VERSION "DNNBNNNYNYNNNNNNNNNNNNNNNNNNNNNNNNNNNNNNNN/4/%%%/4/'%**4NNN///"

NS_ :

BS_:

BU_: ADAS SENP ECU2 ECU3 ECU4 ECU5 ECU6 ECU7 ECU8 ECU9 ECU10 ECU11 ECU12 ECU13 ECU14 ECU15 ECU16 Tester Default_Receiver Handler

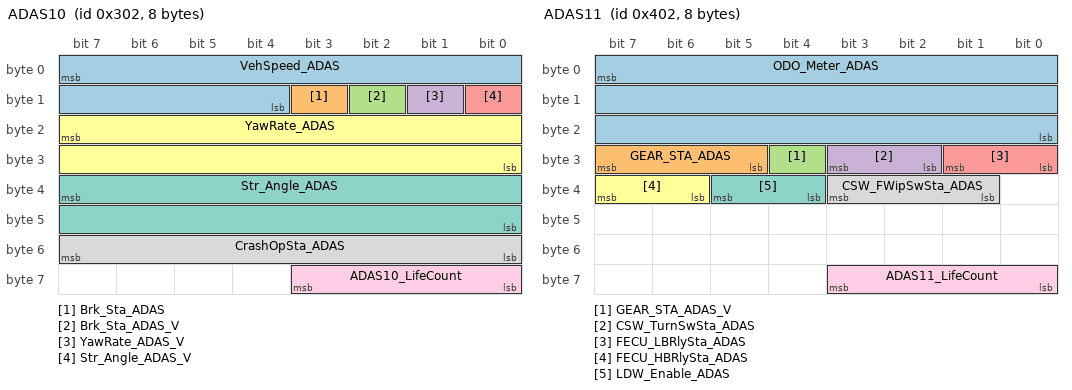
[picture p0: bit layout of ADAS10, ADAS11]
BO_ 770 ADAS10: 8 ADAS
 SG_ VehSpeed_ADAS : 7|12@0+ (0.125,0) [0|0] "km/h"  SENP
 SG_ Brk_Sta_ADAS : 11|1@0+ (1,0) [0|0] ""  SENP
 SG_ Brk_Sta_ADAS_V : 10|1@0+ (1,0) [0|0] ""  SENP
 SG_ YawRate_ADAS_V : 9|1@0+ (1,0) [0|0] ""  SENP
 SG_ Str_Angle_ADAS_V : 8|1@0+ (1,0) [0|0] ""  SENP
 SG_ YawRate_ADAS : 23|16@0+ (0.1,-100) [0|0] "deg/s"  SENP
 SG_ Str_Angle_ADAS : 39|16@0+ (0.1,-900) [0|0] "deg"  SENP
 SG_ CrashOpSta_ADAS : 55|8@0+ (1,0) [0|0] ""  SENP
 SG_ ADAS10_LifeCount : 59|4@0+ (1,0) [0|0] ""  SENP

BO_ 1026 ADAS11: 8 ADAS
 SG_ ODO_Meter_ADAS : 7|24@0+ (1,0) [0|0] "km"  SENP
 SG_ GEAR_STA_ADAS : 31|3@0+ (1,0) [0|0] ""  SENP
 SG_ GEAR_STA_ADAS_V : 28|1@0+ (1,0) [0|0] ""  SENP
 SG_ CSW_TurnSwSta_ADAS : 27|2@0+ (1,0) [0|0] ""  SENP
 SG_ FECU_LBRlySta_ADAS : 25|2@0+ (1,0) [0|0] ""  SENP
 SG_ FECU_HBRlySta_ADAS : 39|2@0+ (1,0) [0|0] ""  SENP
 SG_ LDW_Enable_ADAS : 37|2@0+ (1,0) [0|0] ""  SENP
 SG_ CSW_FWipSwSta_ADAS : 35|3@0+ (1,0) [0|0] ""  SENP
 SG_ ADAS11_LifeCount : 59|4@0+ (1,0) [0|0] ""  SENP

BO_ 1537 CaliCmd1: 8 ADAS
 SG_ EyeQ3_Aim_Request : 7|8@0+ (1,0) [0|0] ""  SENP

BO_ 1808 NMmADAS: 8 ADAS
 SG_ NM_ADAS_Zero_Byte : 7|8@0+ (1,0) [0|0] ""  Default_Receiver
 SG_ NM_ADAS_D_ES : 15|2@0+ (1,0) [0|0] ""  Default_Receiver
 SG_ NM_ADAS_AR : 10|1@0+ (1,0) [0|0] ""  SENP,ECU2,ECU3,ECU4,ECU5,ECU6,ECU7,ECU8,ECU9,ECU10,ECU11,ECU12,ECU13,ECU14,ECU15,ECU16,Tester
 SG_ NM_ADAS_SC : 9|2@0+ (1,0) [0|0] ""  SENP,ECU2,ECU3,ECU4,ECU5,ECU6,ECU7,ECU8,ECU9,ECU10,ECU11,ECU12,ECU13,ECU14,ECU15,ECU16,Tester
 SG_ NM_ADAS_AC : 23|16@0+ (1,0) [0|0] ""  Default_Receiver

BO_ 1919 DiagPhysReqToSENP: 8 ADAS
 SG_ DiagPhysReqToSENP : 7|64@0+ (1,0) [0|0] ""  SENP

BO_ 2000 DiagFuncReqFT: 8 ADAS
 SG_ DiagFuncReq : 7|64@0+ (1,0) [0|0] ""  SENP,ECU11,Default_Receiver

BO_ 784 SENP1: 8 SENP
 SG_ ME_AEB_StAFCW : 7|16@0+ (1,0) [0|0] ""  ADAS
 SG_ ME_AEB_StBFCV : 23|16@0+ (1,0) [0|0] ""  ADAS
 SG_ ME_Warning_P_Ver : 39|8@0+ (1,0) [0|0] "counter"  ADAS
 SG_ ME_AEB_MgCnt : 47|2@0+ (1,0) [0|0] ""  ADAS
 SG_ ME_AEB_Mg_V : 45|1@0+ (1,0) [0|0] ""  ADAS

BO_ 785 SENP2: 8 SENP
 SG_ ME_PEDS_L1FCW : 7|16@0+ (1,0) [0|0] ""  ADAS
 SG_ ME_PEDS_L2Prfill : 23|16@0+ (1,0) [0|0] ""  ADAS
 SG_ ME_PEDS_L3Brking : 39|16@0+ (1,0) [0|0] ""  ADAS
 SG_ ME_PEDS_MgCnt : 55|2@0+ (1,0) [0|0] ""  ADAS
 SG_ ME_PEDS_Mg_V : 53|1@0+ (1,0) [0|0] ""  ADAS

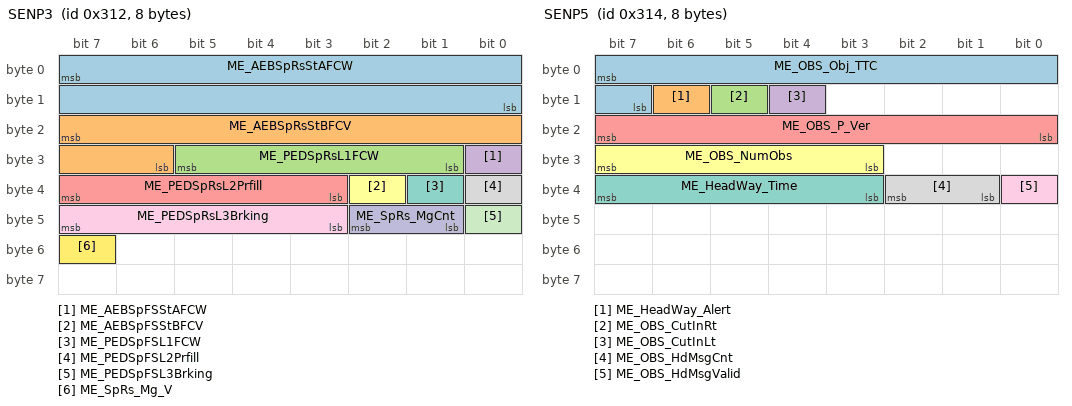
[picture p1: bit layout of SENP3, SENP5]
BO_ 786 SENP3: 8 SENP
 SG_ ME_AEBSpRsStAFCW : 7|16@0+ (1,0) [0|0] ""  ADAS
 SG_ ME_AEBSpRsStBFCV : 23|10@0+ (1,0) [0|0] ""  ADAS
 SG_ ME_PEDSpRsL1FCW : 29|5@0+ (1,0) [0|0] ""  ADAS
 SG_ ME_AEBSpFSStAFCW : 24|1@0+ (1,0) [0|0] ""  ADAS
 SG_ ME_PEDSpRsL2Prfill : 39|5@0+ (1,0) [0|0] ""  ADAS
 SG_ ME_AEBSpFSStBFCV : 34|1@0+ (1,0) [0|0] ""  ADAS
 SG_ ME_PEDSpFSL1FCW : 33|1@0+ (1,0) [0|0] ""  ADAS
 SG_ ME_PEDSpFSL2Prfill : 32|1@0+ (1,0) [0|0] ""  ADAS
 SG_ ME_PEDSpRsL3Brking : 47|5@0+ (1,0) [0|0] ""  ADAS
 SG_ ME_SpRs_MgCnt : 42|2@0+ (1,0) [0|0] ""  ADAS
 SG_ ME_PEDSpFSL3Brking : 40|1@0+ (1,0) [0|0] ""  ADAS
 SG_ ME_SpRs_Mg_V : 55|1@0+ (1,0) [0|0] ""  ADAS

BO_ 787 SENP4: 8 SENP
 SG_ ME_FS_P_Ver : 7|8@0+ (1,0) [0|0] "counter"  ADAS
 SG_ ME_FS_Info_MgCnt : 15|2@0+ (1,0) [0|0] ""  ADAS
 SG_ ME_FS_LowSun : 13|2@0+ (1,0) [0|0] ""  ADAS
 SG_ ME_FS_BlurImage : 11|2@0+ (1,0) [0|0] ""  ADAS
 SG_ ME_FS_FullBlock : 9|2@0+ (1,0) [0|0] ""  ADAS
 SG_ ME_FS_PatialBlock : 23|2@0+ (1,0) [0|0] ""  ADAS
 SG_ ME_FS_Splash : 21|2@0+ (1,0) [0|0] ""  ADAS
 SG_ ME_FS_SmearSpot : 19|2@0+ (1,0) [0|0] ""  ADAS
 SG_ ME_FS_SunRay : 17|2@0+ (1,0) [0|0] ""  ADAS
 SG_ ME_FS_SelfGlare : 31|2@0+ (1,0) [0|0] ""  ADAS
 SG_ ME_FS_FrozenWsd : 29|2@0+ (1,0) [0|0] ""  ADAS
 SG_ ME_Maintenance : 27|1@0+ (1,0) [0|0] ""  ADAS
 SG_ ME_Failsafe : 26|1@0+ (1,0) [0|0] ""  ADAS
 SG_ ME_FS_outOfFocus : 25|1@0+ (1,0) [0|0] ""  ADAS
 SG_ ME_FS_OOCY : 24|1@0+ (1,0) [0|0] ""  ADAS
 SG_ ME_FS_OOCH : 39|1@0+ (1,0) [0|0] ""  ADAS
 SG_ ME_FS_TSR_OOCY : 38|1@0+ (1,0) [0|0] ""  ADAS
 SG_ ME_FS_TSR_OOCP : 37|1@0+ (1,0) [0|0] ""  ADAS
 SG_ ME_FS_Info_Mg_V : 36|1@0+ (1,0) [0|0] ""  ADAS

BO_ 788 SENP5: 8 SENP
 SG_ ME_OBS_Obj_TTC : 7|9@0+ (0.01,0) [0|0] "sec"  ADAS
 SG_ ME_HeadWay_Alert : 14|1@0+ (1,0) [0|0] ""  ADAS
 SG_ ME_OBS_CutInRt : 13|1@0+ (1,0) [0|0] ""  ADAS
 SG_ ME_OBS_CutInLt : 12|1@0+ (1,0) [0|0] ""  ADAS
 SG_ ME_OBS_P_Ver : 23|8@0+ (1,0) [0|0] "counter"  ADAS
 SG_ ME_OBS_NumObs : 31|5@0+ (1,0) [0|0] "counter"  ADAS
 SG_ ME_HeadWay_Time : 39|5@0+ (0.1,0) [0|0] "counter"  ADAS
 SG_ ME_OBS_HdMsgCnt : 34|2@0+ (1,0) [0|0] ""  ADAS
 SG_ ME_OBS_HdMsgValid : 32|1@0+ (1,0) [0|0] ""  ADAS

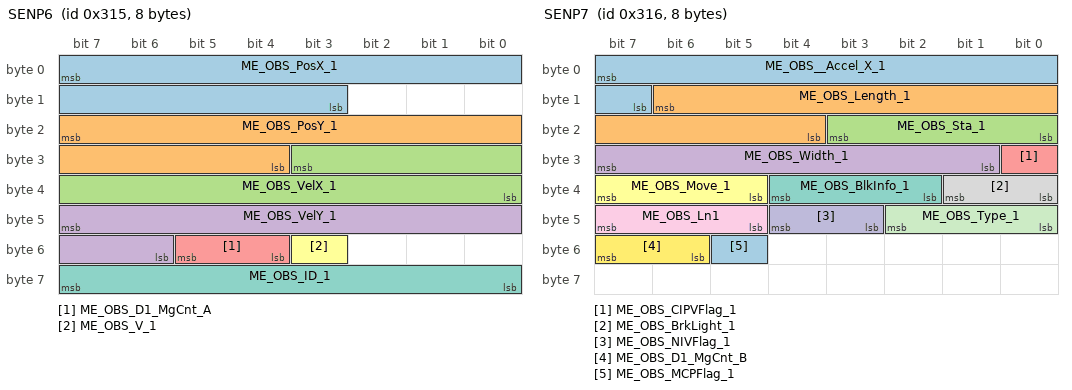
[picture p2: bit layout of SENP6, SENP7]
BO_ 789 SENP6: 8 SENP
 SG_ ME_OBS_PosX_1 : 7|13@0+ (0.05,0) [0|0] "counter"  ADAS
 SG_ ME_OBS_PosY_1 : 23|12@0+ (0.05,-102.4) [0|0] "m"  ADAS
 SG_ ME_OBS_VelX_1 : 27|12@0+ (0.05,-100) [0|0] "counter"  ADAS
 SG_ ME_OBS_VelY_1 : 47|10@0+ (0.05,-25) [0|0] "m/s"  ADAS
 SG_ ME_OBS_D1_MgCnt_A : 53|2@0+ (1,0) [0|0] ""  ADAS
 SG_ ME_OBS_V_1 : 51|1@0+ (1,0) [0|0] ""  ADAS
 SG_ ME_OBS_ID_1 : 63|8@0+ (1,0) [0|0] "counter"  ADAS

BO_ 790 SENP7: 8 SENP
 SG_ ME_OBS__Accel_X_1 : 7|9@0+ (0.05,-12.8) [0|0] "m/s^2"  ADAS
 SG_ ME_OBS_Length_1 : 14|11@0+ (0.05,0) [0|0] "m"  ADAS
 SG_ ME_OBS_Sta_1 : 19|4@0+ (1,0) [0|0] ""  ADAS
 SG_ ME_OBS_Width_1 : 31|7@0+ (0.05,0) [0|0] "m"  ADAS
 SG_ ME_OBS_CIPVFlag_1 : 24|1@0+ (1,0) [0|0] ""  ADAS
 SG_ ME_OBS_Move_1 : 39|3@0+ (1,0) [0|0] ""  ADAS
 SG_ ME_OBS_BlkInfo_1 : 36|3@0+ (1,0) [0|0] ""  ADAS
 SG_ ME_OBS_BrkLight_1 : 33|2@0+ (1,0) [0|0] ""  ADAS
 SG_ ME_OBS_Ln1 : 47|3@0+ (1,0) [0|0] ""  ADAS
 SG_ ME_OBS_NIVFlag_1 : 44|2@0+ (1,0) [0|0] ""  ADAS
 SG_ ME_OBS_Type_1 : 42|3@0+ (1,0) [0|0] ""  ADAS
 SG_ ME_OBS_D1_MgCnt_B : 55|2@0+ (1,0) [0|0] ""  ADAS
 SG_ ME_OBS_MCPFlag_1 : 53|1@0+ (1,0) [0|0] ""  ADAS

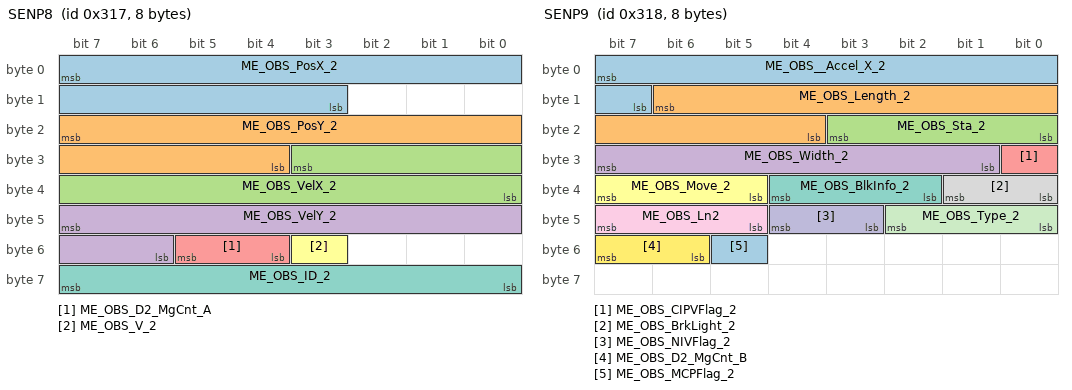
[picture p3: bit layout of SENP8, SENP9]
BO_ 791 SENP8: 8 SENP
 SG_ ME_OBS_PosX_2 : 7|13@0+ (0.05,0) [0|0] "counter"  ADAS
 SG_ ME_OBS_PosY_2 : 23|12@0+ (0.05,-102.4) [0|0] "m"  ADAS
 SG_ ME_OBS_VelX_2 : 27|12@0+ (0.05,-100) [0|0] "counter"  ADAS
 SG_ ME_OBS_VelY_2 : 47|10@0+ (0.05,-25) [0|0] "m/s"  ADAS
 SG_ ME_OBS_D2_MgCnt_A : 53|2@0+ (1,0) [0|0] ""  ADAS
 SG_ ME_OBS_V_2 : 51|1@0+ (1,0) [0|0] ""  ADAS
 SG_ ME_OBS_ID_2 : 63|8@0+ (1,0) [0|0] "counter"  ADAS

BO_ 792 SENP9: 8 SENP
 SG_ ME_OBS__Accel_X_2 : 7|9@0+ (0.05,-12.8) [0|0] "m/s^2"  ADAS
 SG_ ME_OBS_Length_2 : 14|11@0+ (0.05,0) [0|0] "m"  ADAS
 SG_ ME_OBS_Sta_2 : 19|4@0+ (1,0) [0|0] ""  ADAS
 SG_ ME_OBS_Width_2 : 31|7@0+ (0.05,0) [0|0] "m"  ADAS
 SG_ ME_OBS_CIPVFlag_2 : 24|1@0+ (1,0) [0|0] ""  ADAS
 SG_ ME_OBS_Move_2 : 39|3@0+ (1,0) [0|0] ""  ADAS
 SG_ ME_OBS_BlkInfo_2 : 36|3@0+ (1,0) [0|0] ""  ADAS
 SG_ ME_OBS_BrkLight_2 : 33|2@0+ (1,0) [0|0] ""  ADAS
 SG_ ME_OBS_Ln2 : 47|3@0+ (1,0) [0|0] ""  ADAS
 SG_ ME_OBS_NIVFlag_2 : 44|2@0+ (1,0) [0|0] ""  ADAS
 SG_ ME_OBS_Type_2 : 42|3@0+ (1,0) [0|0] ""  ADAS
 SG_ ME_OBS_D2_MgCnt_B : 55|2@0+ (1,0) [0|0] ""  ADAS
 SG_ ME_OBS_MCPFlag_2 : 53|1@0+ (1,0) [0|0] ""  ADAS

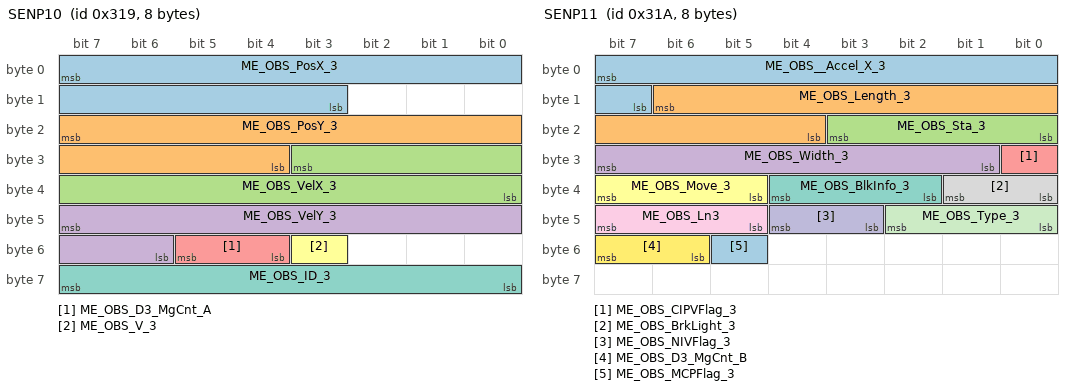
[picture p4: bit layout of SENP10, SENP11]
BO_ 793 SENP10: 8 SENP
 SG_ ME_OBS_PosX_3 : 7|13@0+ (0.05,0) [0|0] "counter"  ADAS
 SG_ ME_OBS_PosY_3 : 23|12@0+ (0.05,-102.4) [0|0] "m"  ADAS
 SG_ ME_OBS_VelX_3 : 27|12@0+ (0.05,-100) [0|0] "counter"  ADAS
 SG_ ME_OBS_VelY_3 : 47|10@0+ (0.05,-25) [0|0] "m/s"  ADAS
 SG_ ME_OBS_D3_MgCnt_A : 53|2@0+ (1,0) [0|0] ""  ADAS
 SG_ ME_OBS_V_3 : 51|1@0+ (1,0) [0|0] ""  ADAS
 SG_ ME_OBS_ID_3 : 63|8@0+ (1,0) [0|0] "counter"  ADAS

BO_ 794 SENP11: 8 SENP
 SG_ ME_OBS__Accel_X_3 : 7|9@0+ (0.05,-12.8) [0|0] "m/s^2"  ADAS
 SG_ ME_OBS_Length_3 : 14|11@0+ (0.05,0) [0|0] "m"  ADAS
 SG_ ME_OBS_Sta_3 : 19|4@0+ (1,0) [0|0] ""  ADAS
 SG_ ME_OBS_Width_3 : 31|7@0+ (0.05,0) [0|0] "m"  ADAS
 SG_ ME_OBS_CIPVFlag_3 : 24|1@0+ (1,0) [0|0] ""  ADAS
 SG_ ME_OBS_Move_3 : 39|3@0+ (1,0) [0|0] ""  ADAS
 SG_ ME_OBS_BlkInfo_3 : 36|3@0+ (1,0) [0|0] ""  ADAS
 SG_ ME_OBS_BrkLight_3 : 33|2@0+ (1,0) [0|0] ""  ADAS
 SG_ ME_OBS_Ln3 : 47|3@0+ (1,0) [0|0] ""  ADAS
 SG_ ME_OBS_NIVFlag_3 : 44|2@0+ (1,0) [0|0] ""  ADAS
 SG_ ME_OBS_Type_3 : 42|3@0+ (1,0) [0|0] ""  ADAS
 SG_ ME_OBS_D3_MgCnt_B : 55|2@0+ (1,0) [0|0] ""  ADAS
 SG_ ME_OBS_MCPFlag_3 : 53|1@0+ (1,0) [0|0] ""  ADAS

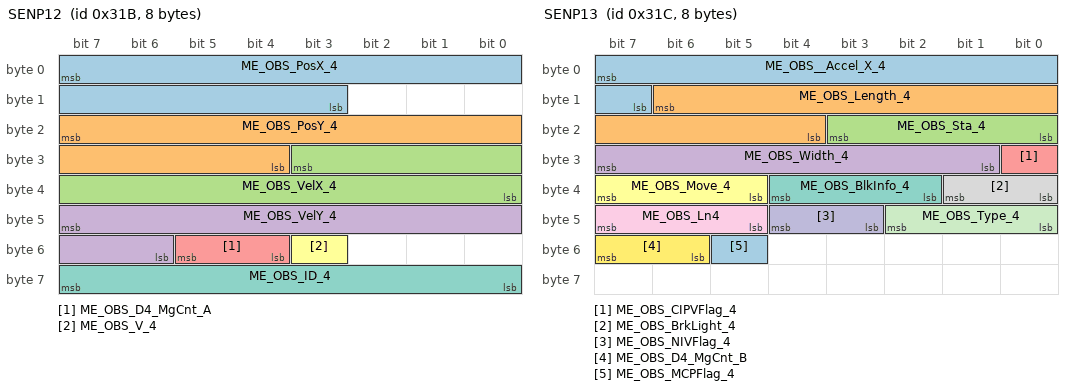
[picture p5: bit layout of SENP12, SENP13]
BO_ 795 SENP12: 8 SENP
 SG_ ME_OBS_PosX_4 : 7|13@0+ (0.05,0) [0|0] "counter"  ADAS
 SG_ ME_OBS_PosY_4 : 23|12@0+ (0.05,-102.4) [0|0] "m"  ADAS
 SG_ ME_OBS_VelX_4 : 27|12@0+ (0.05,-100) [0|0] "counter"  ADAS
 SG_ ME_OBS_VelY_4 : 47|10@0+ (0.05,-25) [0|0] "m/s"  ADAS
 SG_ ME_OBS_D4_MgCnt_A : 53|2@0+ (1,0) [0|0] ""  ADAS
 SG_ ME_OBS_V_4 : 51|1@0+ (1,0) [0|0] ""  ADAS
 SG_ ME_OBS_ID_4 : 63|8@0+ (1,0) [0|0] "counter"  ADAS

BO_ 796 SENP13: 8 SENP
 SG_ ME_OBS__Accel_X_4 : 7|9@0+ (0.05,-12.8) [0|0] "m/s^2"  ADAS
 SG_ ME_OBS_Length_4 : 14|11@0+ (0.05,0) [0|0] "m"  ADAS
 SG_ ME_OBS_Sta_4 : 19|4@0+ (1,0) [0|0] ""  ADAS
 SG_ ME_OBS_Width_4 : 31|7@0+ (0.05,0) [0|0] "m"  ADAS
 SG_ ME_OBS_CIPVFlag_4 : 24|1@0+ (1,0) [0|0] ""  ADAS
 SG_ ME_OBS_Move_4 : 39|3@0+ (1,0) [0|0] ""  ADAS
 SG_ ME_OBS_BlkInfo_4 : 36|3@0+ (1,0) [0|0] ""  ADAS
 SG_ ME_OBS_BrkLight_4 : 33|2@0+ (1,0) [0|0] ""  ADAS
 SG_ ME_OBS_Ln4 : 47|3@0+ (1,0) [0|0] ""  ADAS
 SG_ ME_OBS_NIVFlag_4 : 44|2@0+ (1,0) [0|0] ""  ADAS
 SG_ ME_OBS_Type_4 : 42|3@0+ (1,0) [0|0] ""  ADAS
 SG_ ME_OBS_D4_MgCnt_B : 55|2@0+ (1,0) [0|0] ""  ADAS
 SG_ ME_OBS_MCPFlag_4 : 53|1@0+ (1,0) [0|0] ""  ADAS

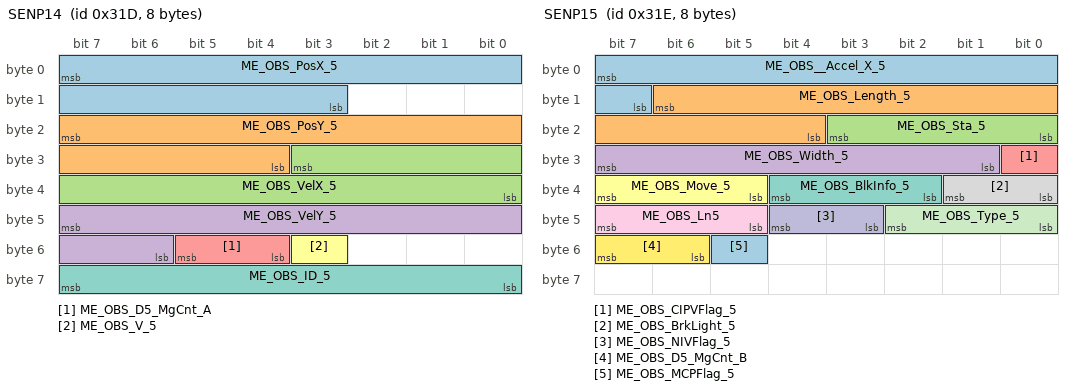
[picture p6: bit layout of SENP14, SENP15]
BO_ 797 SENP14: 8 SENP
 SG_ ME_OBS_PosX_5 : 7|13@0+ (0.05,0) [0|0] "counter"  ADAS
 SG_ ME_OBS_PosY_5 : 23|12@0+ (0.05,-102.4) [0|0] "m"  ADAS
 SG_ ME_OBS_VelX_5 : 27|12@0+ (0.05,-100) [0|0] "counter"  ADAS
 SG_ ME_OBS_VelY_5 : 47|10@0+ (0.05,-25) [0|0] "m/s"  ADAS
 SG_ ME_OBS_D5_MgCnt_A : 53|2@0+ (1,0) [0|0] ""  ADAS
 SG_ ME_OBS_V_5 : 51|1@0+ (1,0) [0|0] ""  ADAS
 SG_ ME_OBS_ID_5 : 63|8@0+ (1,0) [0|0] "counter"  ADAS

BO_ 798 SENP15: 8 SENP
 SG_ ME_OBS__Accel_X_5 : 7|9@0+ (0.05,-12.8) [0|0] "m/s^2"  ADAS
 SG_ ME_OBS_Length_5 : 14|11@0+ (0.05,0) [0|0] "m"  ADAS
 SG_ ME_OBS_Sta_5 : 19|4@0+ (1,0) [0|0] ""  ADAS
 SG_ ME_OBS_Width_5 : 31|7@0+ (0.05,0) [0|0] "m"  ADAS
 SG_ ME_OBS_CIPVFlag_5 : 24|1@0+ (1,0) [0|0] ""  ADAS
 SG_ ME_OBS_Move_5 : 39|3@0+ (1,0) [0|0] ""  ADAS
 SG_ ME_OBS_BlkInfo_5 : 36|3@0+ (1,0) [0|0] ""  ADAS
 SG_ ME_OBS_BrkLight_5 : 33|2@0+ (1,0) [0|0] ""  ADAS
 SG_ ME_OBS_Ln5 : 47|3@0+ (1,0) [0|0] ""  ADAS
 SG_ ME_OBS_NIVFlag_5 : 44|2@0+ (1,0) [0|0] ""  ADAS
 SG_ ME_OBS_Type_5 : 42|3@0+ (1,0) [0|0] ""  ADAS
 SG_ ME_OBS_D5_MgCnt_B : 55|2@0+ (1,0) [0|0] ""  ADAS
 SG_ ME_OBS_MCPFlag_5 : 53|1@0+ (1,0) [0|0] ""  ADAS

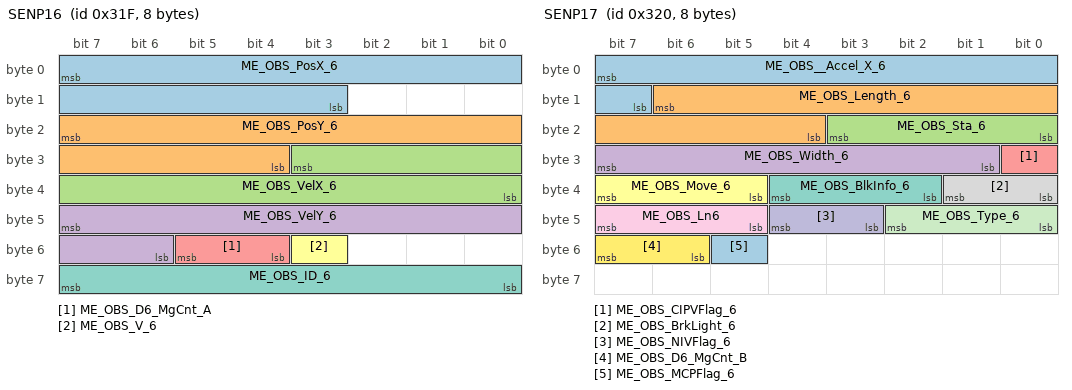
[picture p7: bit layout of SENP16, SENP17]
BO_ 799 SENP16: 8 SENP
 SG_ ME_OBS_PosX_6 : 7|13@0+ (0.05,0) [0|0] "counter"  ADAS
 SG_ ME_OBS_PosY_6 : 23|12@0+ (0.05,-102.4) [0|0] "m"  ADAS
 SG_ ME_OBS_VelX_6 : 27|12@0+ (0.05,-100) [0|0] "counter"  ADAS
 SG_ ME_OBS_VelY_6 : 47|10@0+ (0.05,-25) [0|0] "m/s"  ADAS
 SG_ ME_OBS_D6_MgCnt_A : 53|2@0+ (1,0) [0|0] ""  ADAS
 SG_ ME_OBS_V_6 : 51|1@0+ (1,0) [0|0] ""  ADAS
 SG_ ME_OBS_ID_6 : 63|8@0+ (1,0) [0|0] "counter"  ADAS

BO_ 800 SENP17: 8 SENP
 SG_ ME_OBS__Accel_X_6 : 7|9@0+ (0.05,-12.8) [0|0] "m/s^2"  ADAS
 SG_ ME_OBS_Length_6 : 14|11@0+ (0.05,0) [0|0] "m"  ADAS
 SG_ ME_OBS_Sta_6 : 19|4@0+ (1,0) [0|0] ""  ADAS
 SG_ ME_OBS_Width_6 : 31|7@0+ (0.05,0) [0|0] "m"  ADAS
 SG_ ME_OBS_CIPVFlag_6 : 24|1@0+ (1,0) [0|0] ""  ADAS
 SG_ ME_OBS_Move_6 : 39|3@0+ (1,0) [0|0] ""  ADAS
 SG_ ME_OBS_BlkInfo_6 : 36|3@0+ (1,0) [0|0] ""  ADAS
 SG_ ME_OBS_BrkLight_6 : 33|2@0+ (1,0) [0|0] ""  ADAS
 SG_ ME_OBS_Ln6 : 47|3@0+ (1,0) [0|0] ""  ADAS
 SG_ ME_OBS_NIVFlag_6 : 44|2@0+ (1,0) [0|0] ""  ADAS
 SG_ ME_OBS_Type_6 : 42|3@0+ (1,0) [0|0] ""  ADAS
 SG_ ME_OBS_D6_MgCnt_B : 55|2@0+ (1,0) [0|0] ""  ADAS
 SG_ ME_OBS_MCPFlag_6 : 53|1@0+ (1,0) [0|0] ""  ADAS

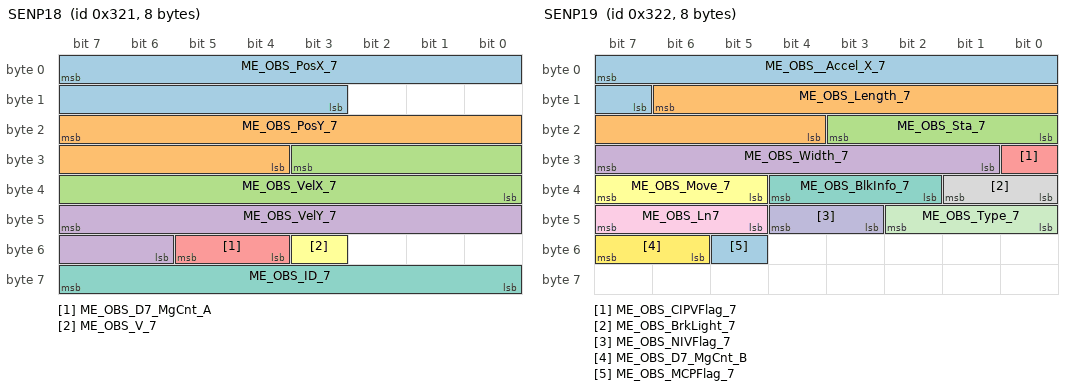
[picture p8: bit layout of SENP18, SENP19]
BO_ 801 SENP18: 8 SENP
 SG_ ME_OBS_PosX_7 : 7|13@0+ (0.05,0) [0|0] "counter"  ADAS
 SG_ ME_OBS_PosY_7 : 23|12@0+ (0.05,-102.4) [0|0] "m"  ADAS
 SG_ ME_OBS_VelX_7 : 27|12@0+ (0.05,-100) [0|0] "counter"  ADAS
 SG_ ME_OBS_VelY_7 : 47|10@0+ (0.05,-25) [0|0] "m/s"  ADAS
 SG_ ME_OBS_D7_MgCnt_A : 53|2@0+ (1,0) [0|0] ""  ADAS
 SG_ ME_OBS_V_7 : 51|1@0+ (1,0) [0|0] ""  ADAS
 SG_ ME_OBS_ID_7 : 63|8@0+ (1,0) [0|0] "counter"  ADAS

BO_ 802 SENP19: 8 SENP
 SG_ ME_OBS__Accel_X_7 : 7|9@0+ (0.05,-12.8) [0|0] "m/s^2"  ADAS
 SG_ ME_OBS_Length_7 : 14|11@0+ (0.05,0) [0|0] "m"  ADAS
 SG_ ME_OBS_Sta_7 : 19|4@0+ (1,0) [0|0] ""  ADAS
 SG_ ME_OBS_Width_7 : 31|7@0+ (0.05,0) [0|0] "m"  ADAS
 SG_ ME_OBS_CIPVFlag_7 : 24|1@0+ (1,0) [0|0] ""  ADAS
 SG_ ME_OBS_Move_7 : 39|3@0+ (1,0) [0|0] ""  ADAS
 SG_ ME_OBS_BlkInfo_7 : 36|3@0+ (1,0) [0|0] ""  ADAS
 SG_ ME_OBS_BrkLight_7 : 33|2@0+ (1,0) [0|0] ""  ADAS
 SG_ ME_OBS_Ln7 : 47|3@0+ (1,0) [0|0] ""  ADAS
 SG_ ME_OBS_NIVFlag_7 : 44|2@0+ (1,0) [0|0] ""  ADAS
 SG_ ME_OBS_Type_7 : 42|3@0+ (1,0) [0|0] ""  ADAS
 SG_ ME_OBS_D7_MgCnt_B : 55|2@0+ (1,0) [0|0] ""  ADAS
 SG_ ME_OBS_MCPFlag_7 : 53|1@0+ (1,0) [0|0] ""  ADAS

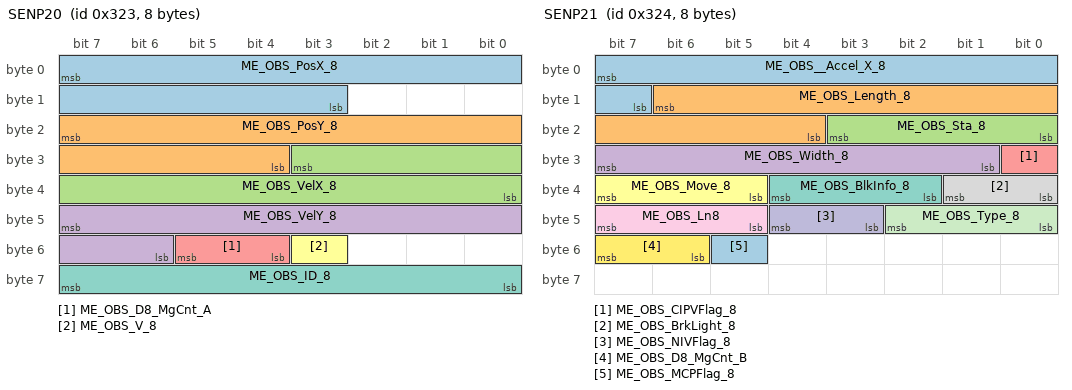
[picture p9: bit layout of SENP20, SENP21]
BO_ 803 SENP20: 8 SENP
 SG_ ME_OBS_PosX_8 : 7|13@0+ (0.05,0) [0|0] "counter"  ADAS
 SG_ ME_OBS_PosY_8 : 23|12@0+ (0.05,-102.4) [0|0] "m"  ADAS
 SG_ ME_OBS_VelX_8 : 27|12@0+ (0.05,-100) [0|0] "counter"  ADAS
 SG_ ME_OBS_VelY_8 : 47|10@0+ (0.05,-25) [0|0] "m/s"  ADAS
 SG_ ME_OBS_D8_MgCnt_A : 53|2@0+ (1,0) [0|0] ""  ADAS
 SG_ ME_OBS_V_8 : 51|1@0+ (1,0) [0|0] ""  ADAS
 SG_ ME_OBS_ID_8 : 63|8@0+ (1,0) [0|0] "counter"  ADAS

BO_ 804 SENP21: 8 SENP
 SG_ ME_OBS__Accel_X_8 : 7|9@0+ (0.05,-12.8) [0|0] "m/s^2"  ADAS
 SG_ ME_OBS_Length_8 : 14|11@0+ (0.05,0) [0|0] "m"  ADAS
 SG_ ME_OBS_Sta_8 : 19|4@0+ (1,0) [0|0] ""  ADAS
 SG_ ME_OBS_Width_8 : 31|7@0+ (0.05,0) [0|0] "m"  ADAS
 SG_ ME_OBS_CIPVFlag_8 : 24|1@0+ (1,0) [0|0] ""  ADAS
 SG_ ME_OBS_Move_8 : 39|3@0+ (1,0) [0|0] ""  ADAS
 SG_ ME_OBS_BlkInfo_8 : 36|3@0+ (1,0) [0|0] ""  ADAS
 SG_ ME_OBS_BrkLight_8 : 33|2@0+ (1,0) [0|0] ""  ADAS
 SG_ ME_OBS_Ln8 : 47|3@0+ (1,0) [0|0] ""  ADAS
 SG_ ME_OBS_NIVFlag_8 : 44|2@0+ (1,0) [0|0] ""  ADAS
 SG_ ME_OBS_Type_8 : 42|3@0+ (1,0) [0|0] ""  ADAS
 SG_ ME_OBS_D8_MgCnt_B : 55|2@0+ (1,0) [0|0] ""  ADAS
 SG_ ME_OBS_MCPFlag_8 : 53|1@0+ (1,0) [0|0] ""  ADAS

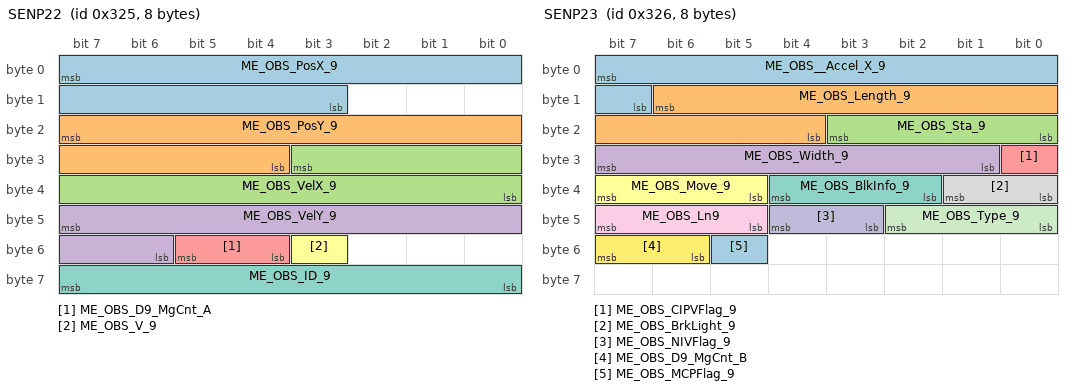
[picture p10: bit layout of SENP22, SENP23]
BO_ 805 SENP22: 8 SENP
 SG_ ME_OBS_PosX_9 : 7|13@0+ (0.05,0) [0|0] "counter"  ADAS
 SG_ ME_OBS_PosY_9 : 23|12@0+ (0.05,-102.4) [0|0] "m"  ADAS
 SG_ ME_OBS_VelX_9 : 27|12@0+ (0.05,-100) [0|0] "counter"  ADAS
 SG_ ME_OBS_VelY_9 : 47|10@0+ (0.05,-25) [0|0] "m/s"  ADAS
 SG_ ME_OBS_D9_MgCnt_A : 53|2@0+ (1,0) [0|0] ""  ADAS
 SG_ ME_OBS_V_9 : 51|1@0+ (1,0) [0|0] ""  ADAS
 SG_ ME_OBS_ID_9 : 63|8@0+ (1,0) [0|0] "counter"  ADAS

BO_ 806 SENP23: 8 SENP
 SG_ ME_OBS__Accel_X_9 : 7|9@0+ (0.05,-12.8) [0|0] "m/s^2"  ADAS
 SG_ ME_OBS_Length_9 : 14|11@0+ (0.05,0) [0|0] "m"  ADAS
 SG_ ME_OBS_Sta_9 : 19|4@0+ (1,0) [0|0] ""  ADAS
 SG_ ME_OBS_Width_9 : 31|7@0+ (0.05,0) [0|0] "m"  ADAS
 SG_ ME_OBS_CIPVFlag_9 : 24|1@0+ (1,0) [0|0] ""  ADAS
 SG_ ME_OBS_Move_9 : 39|3@0+ (1,0) [0|0] ""  ADAS
 SG_ ME_OBS_BlkInfo_9 : 36|3@0+ (1,0) [0|0] ""  ADAS
 SG_ ME_OBS_BrkLight_9 : 33|2@0+ (1,0) [0|0] ""  ADAS
 SG_ ME_OBS_Ln9 : 47|3@0+ (1,0) [0|0] ""  ADAS
 SG_ ME_OBS_NIVFlag_9 : 44|2@0+ (1,0) [0|0] ""  ADAS
 SG_ ME_OBS_Type_9 : 42|3@0+ (1,0) [0|0] ""  ADAS
 SG_ ME_OBS_D9_MgCnt_B : 55|2@0+ (1,0) [0|0] ""  ADAS
 SG_ ME_OBS_MCPFlag_9 : 53|1@0+ (1,0) [0|0] ""  ADAS

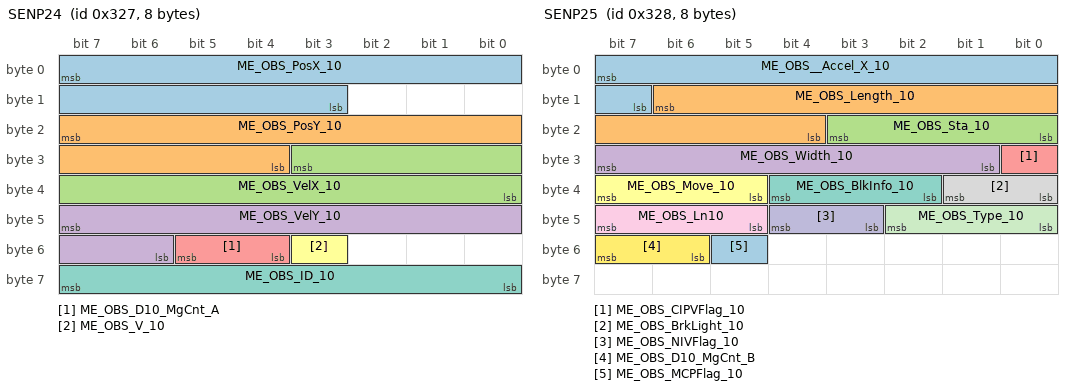
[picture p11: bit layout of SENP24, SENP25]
BO_ 807 SENP24: 8 SENP
 SG_ ME_OBS_PosX_10 : 7|13@0+ (0.05,0) [0|0] "counter"  ADAS
 SG_ ME_OBS_PosY_10 : 23|12@0+ (0.05,-102.4) [0|0] "m"  ADAS
 SG_ ME_OBS_VelX_10 : 27|12@0+ (0.05,-100) [0|0] "counter"  ADAS
 SG_ ME_OBS_VelY_10 : 47|10@0+ (0.05,-25) [0|0] "m/s"  ADAS
 SG_ ME_OBS_D10_MgCnt_A : 53|2@0+ (1,0) [0|0] ""  ADAS
 SG_ ME_OBS_V_10 : 51|1@0+ (1,0) [0|0] ""  ADAS
 SG_ ME_OBS_ID_10 : 63|8@0+ (1,0) [0|0] "counter"  ADAS

BO_ 808 SENP25: 8 SENP
 SG_ ME_OBS__Accel_X_10 : 7|9@0+ (0.05,-12.8) [0|0] "m/s^2"  ADAS
 SG_ ME_OBS_Length_10 : 14|11@0+ (0.05,0) [0|0] "m"  ADAS
 SG_ ME_OBS_Sta_10 : 19|4@0+ (1,0) [0|0] ""  ADAS
 SG_ ME_OBS_Width_10 : 31|7@0+ (0.05,0) [0|0] "m"  ADAS
 SG_ ME_OBS_CIPVFlag_10 : 24|1@0+ (1,0) [0|0] ""  ADAS
 SG_ ME_OBS_Move_10 : 39|3@0+ (1,0) [0|0] ""  ADAS
 SG_ ME_OBS_BlkInfo_10 : 36|3@0+ (1,0) [0|0] ""  ADAS
 SG_ ME_OBS_BrkLight_10 : 33|2@0+ (1,0) [0|0] ""  ADAS
 SG_ ME_OBS_Ln10 : 47|3@0+ (1,0) [0|0] ""  ADAS
 SG_ ME_OBS_NIVFlag_10 : 44|2@0+ (1,0) [0|0] ""  ADAS
 SG_ ME_OBS_Type_10 : 42|3@0+ (1,0) [0|0] ""  ADAS
 SG_ ME_OBS_D10_MgCnt_B : 55|2@0+ (1,0) [0|0] ""  ADAS
 SG_ ME_OBS_MCPFlag_10 : 53|1@0+ (1,0) [0|0] ""  ADAS

BO_ 809 SENP43: 8 SENP
 SG_ ME_LDW_LineDis_L : 7|9@0+ (0.01,-2) [0|0] "m"  ADAS
 SG_ ME_LDW_LtLn_V : 14|1@0+ (1,0) [0|0] ""  ADAS
 SG_ ME_LDW_LnRt_V : 13|1@0+ (1,0) [0|0] ""  ADAS
 SG_ ME_LDW_RTA : 12|1@0+ (1,0) [0|0] ""  ADAS
 SG_ ME_LDW_NA_RsSpeed : 11|1@0+ (1,0) [0|0] ""  ADAS
 SG_ ME_LDW_NA_RsSingle : 10|1@0+ (1,0) [0|0] ""  ADAS
 SG_ ME_LDW_NA_RsNarrow : 9|1@0+ (1,0) [0|0] ""  ADAS
 SG_ ME_LDW_RsStr : 8|1@0+ (1,0) [0|0] ""  ADAS
 SG_ ME_LDW_LineDis_R : 23|9@0+ (0.01,-2) [0|0] "m"  ADAS
 SG_ ME_LDW_RsBlink_R : 30|1@0+ (1,0) [0|0] ""  ADAS
 SG_ ME_LDW_RsBlink_L : 29|1@0+ (1,0) [0|0] ""  ADAS
 SG_ ME_LDW_RsBrake : 28|1@0+ (1,0) [0|0] ""  ADAS
 SG_ ME_LDW_RsAccel : 27|1@0+ (1,0) [0|0] ""  ADAS
 SG_ ME_LDW_RsGen : 26|1@0+ (1,0) [0|0] ""  ADAS
 SG_ ME_LDW_TLC_L : 39|8@0+ (0.01,0) [0|0] "sec"  ADAS
 SG_ ME_LDW_TLC_R : 47|8@0+ (0.01,0) [0|0] "sec"  ADAS
 SG_ ME_LDW_MgCnt : 55|2@0+ (1,0) [0|0] ""  ADAS
 SG_ ME_LDW_Sta_L : 53|2@0+ (1,0) [0|0] ""  ADAS
 SG_ ME_LDW_Sta_R : 51|2@0+ (1,0) [0|0] ""  ADAS
 SG_ ME_LDW_Mg_V : 49|1@0+ (1,0) [0|0] ""  ADAS

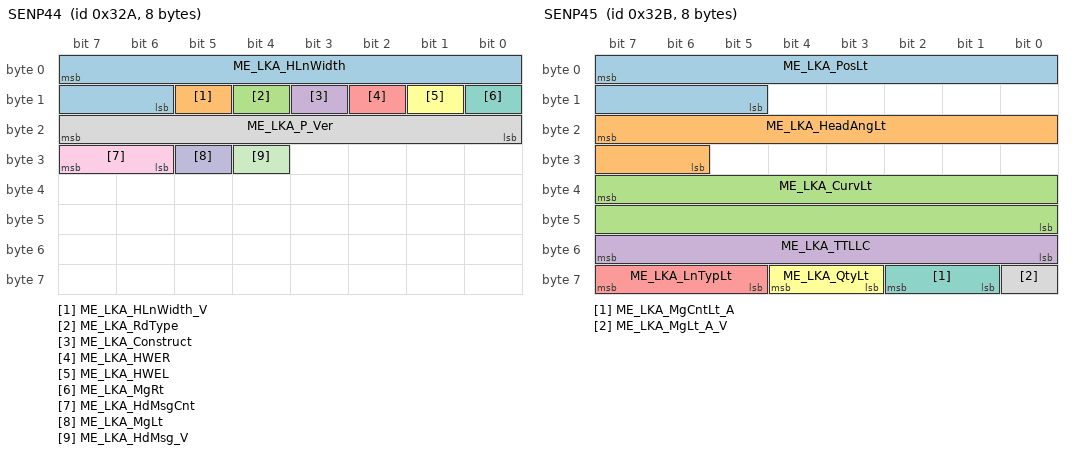
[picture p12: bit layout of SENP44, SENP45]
BO_ 810 SENP44: 8 SENP
 SG_ ME_LKA_HLnWidth : 7|10@0+ (0.01,0) [0|0] "m"  ADAS
 SG_ ME_LKA_HLnWidth_V : 13|1@0+ (1,0) [0|0] ""  ADAS
 SG_ ME_LKA_RdType : 12|1@0+ (1,0) [0|0] ""  ADAS
 SG_ ME_LKA_Construct : 11|1@0+ (1,0) [0|0] ""  ADAS
 SG_ ME_LKA_HWER : 10|1@0+ (1,0) [0|0] ""  ADAS
 SG_ ME_LKA_HWEL : 9|1@0+ (1,0) [0|0] ""  ADAS
 SG_ ME_LKA_MgRt : 8|1@0+ (1,0) [0|0] ""  ADAS
 SG_ ME_LKA_P_Ver : 23|8@0+ (1,0) [0|0] "counter"  ADAS
 SG_ ME_LKA_HdMsgCnt : 31|2@0+ (1,0) [0|0] ""  ADAS
 SG_ ME_LKA_MgLt : 29|1@0+ (1,0) [0|0] ""  ADAS
 SG_ ME_LKA_HdMsg_V : 28|1@0+ (1,0) [0|0] ""  ADAS

BO_ 811 SENP45: 8 SENP
 SG_ ME_LKA_PosLt : 7|11@0+ (0.01,-10) [0|0] "meter"  ADAS
 SG_ ME_LKA_HeadAngLt : 23|10@0+ (0.000977,-0.357) [0|0] "radians"  ADAS
 SG_ ME_LKA_CurvLt : 39|16@0+ (9.77E-007,-0.032) [0|0] "1/meter"  ADAS
 SG_ ME_LKA_TTLLC : 55|8@0+ (0.01,0) [0|0] "sec"  ADAS
 SG_ ME_LKA_LnTypLt : 63|3@0+ (1,0) [0|0] ""  ADAS
 SG_ ME_LKA_QtyLt : 60|2@0+ (1,0) [0|0] ""  ADAS
 SG_ ME_LKA_MgCntLt_A : 58|2@0+ (1,0) [0|0] ""  ADAS
 SG_ ME_LKA_MgLt_A_V : 56|1@0+ (1,0) [0|0] ""  ADAS

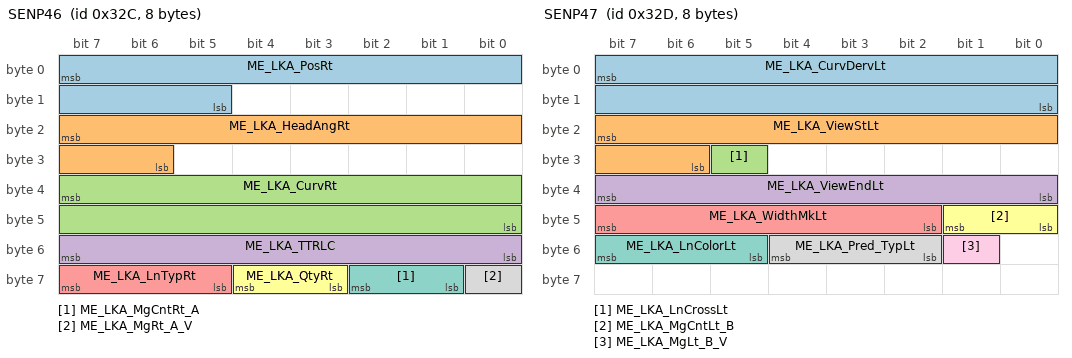
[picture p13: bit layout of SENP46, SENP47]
BO_ 812 SENP46: 8 SENP
 SG_ ME_LKA_PosRt : 7|11@0+ (0.01,-10) [0|0] "meter"  ADAS
 SG_ ME_LKA_HeadAngRt : 23|10@0+ (0.000977,-0.357) [0|0] "radians"  ADAS
 SG_ ME_LKA_CurvRt : 39|16@0+ (9.77E-007,-0.032) [0|0] "1/meter"  ADAS
 SG_ ME_LKA_TTRLC : 55|8@0+ (0.01,0) [0|0] "sec"  ADAS
 SG_ ME_LKA_LnTypRt : 63|3@0+ (1,0) [0|0] ""  ADAS
 SG_ ME_LKA_QtyRt : 60|2@0+ (1,0) [0|0] ""  ADAS
 SG_ ME_LKA_MgCntRt_A : 58|2@0+ (1,0) [0|0] ""  ADAS
 SG_ ME_LKA_MgRt_A_V : 56|1@0+ (1,0) [0|0] ""  ADAS

BO_ 813 SENP47: 8 SENP
 SG_ ME_LKA_CurvDervLt : 7|16@0+ (3.73E-009,-0.000122) [0|0] "1/meter^2"  ADAS
 SG_ ME_LKA_ViewStLt : 23|10@0+ (0.1,0) [0|0] "meter"  ADAS
 SG_ ME_LKA_LnCrossLt : 29|1@0+ (1,0) [0|0] ""  ADAS
 SG_ ME_LKA_ViewEndLt : 39|8@0+ (1,0) [0|0] "meter"  ADAS
 SG_ ME_LKA_WidthMkLt : 47|6@0+ (0.01,0) [0|0] "meter"  ADAS
 SG_ ME_LKA_MgCntLt_B : 41|2@0+ (1,0) [0|0] ""  ADAS
 SG_ ME_LKA_LnColorLt : 55|3@0+ (1,0) [0|0] ""  ADAS
 SG_ ME_LKA_Pred_TypLt : 52|3@0+ (1,0) [0|0] ""  ADAS
 SG_ ME_LKA_MgLt_B_V : 49|1@0+ (1,0) [0|0] ""  ADAS

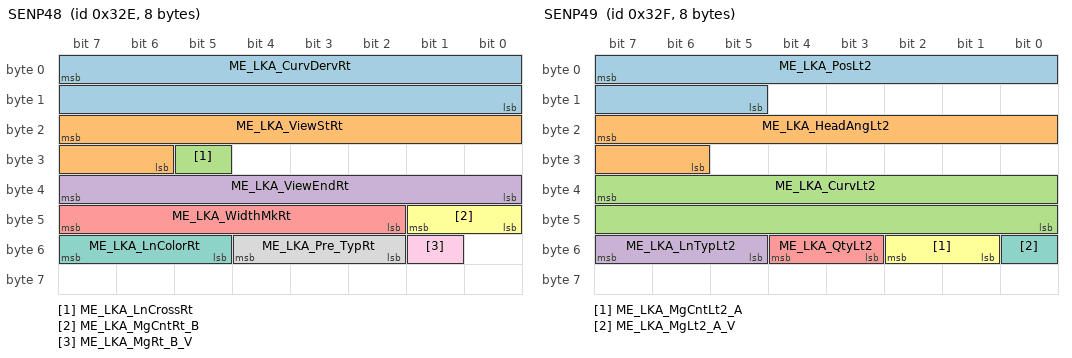
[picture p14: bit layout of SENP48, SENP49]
BO_ 814 SENP48: 8 SENP
 SG_ ME_LKA_CurvDervRt : 7|16@0+ (3.73E-009,-0.000122) [0|0] "1/meter^2"  ADAS
 SG_ ME_LKA_ViewStRt : 23|10@0+ (0.1,0) [0|0] "meter"  ADAS
 SG_ ME_LKA_LnCrossRt : 29|1@0+ (1,0) [0|0] ""  ADAS
 SG_ ME_LKA_ViewEndRt : 39|8@0+ (1,0) [0|0] "meter"  ADAS
 SG_ ME_LKA_WidthMkRt : 47|6@0+ (0.01,0) [0|0] "meter"  ADAS
 SG_ ME_LKA_MgCntRt_B : 41|2@0+ (1,0) [0|0] ""  ADAS
 SG_ ME_LKA_LnColorRt : 55|3@0+ (1,0) [0|0] ""  ADAS
 SG_ ME_LKA_Pre_TypRt : 52|3@0+ (1,0) [0|0] ""  ADAS
 SG_ ME_LKA_MgRt_B_V : 49|1@0+ (1,0) [0|0] ""  ADAS

BO_ 815 SENP49: 8 SENP
 SG_ ME_LKA_PosLt2 : 7|11@0+ (0.01,-10) [0|0] "meter"  ADAS
 SG_ ME_LKA_HeadAngLt2 : 23|10@0+ (0.000977,-0.357) [0|0] "radians"  ADAS
 SG_ ME_LKA_CurvLt2 : 39|16@0+ (9.77E-007,-0.032) [0|0] "1/meter"  ADAS
 SG_ ME_LKA_LnTypLt2 : 55|3@0+ (1,0) [0|0] ""  ADAS
 SG_ ME_LKA_QtyLt2 : 52|2@0+ (1,0) [0|0] ""  ADAS
 SG_ ME_LKA_MgCntLt2_A : 50|2@0+ (1,0) [0|0] ""  ADAS
 SG_ ME_LKA_MgLt2_A_V : 48|1@0+ (1,0) [0|0] ""  ADAS

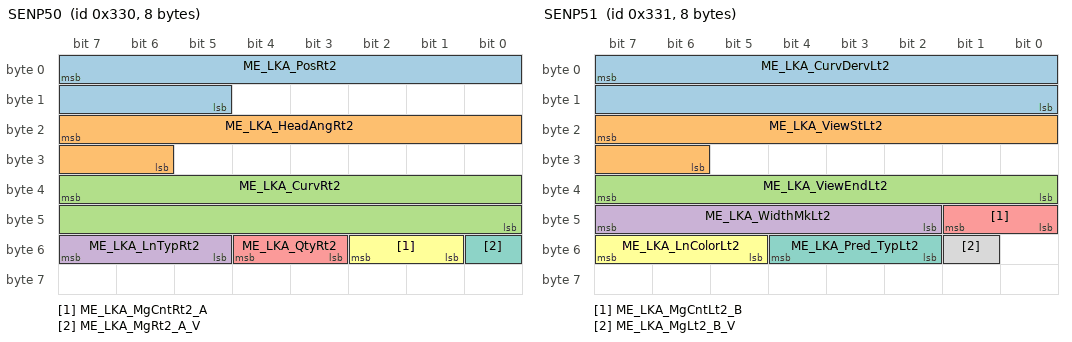
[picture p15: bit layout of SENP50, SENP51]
BO_ 816 SENP50: 8 SENP
 SG_ ME_LKA_PosRt2 : 7|11@0+ (0.01,-10) [0|0] "meter"  ADAS
 SG_ ME_LKA_HeadAngRt2 : 23|10@0+ (0.000977,-0.357) [0|0] "radians"  ADAS
 SG_ ME_LKA_CurvRt2 : 39|16@0+ (9.77E-007,-0.032) [0|0] "1/meter"  ADAS
 SG_ ME_LKA_LnTypRt2 : 55|3@0+ (1,0) [0|0] ""  ADAS
 SG_ ME_LKA_QtyRt2 : 52|2@0+ (1,0) [0|0] ""  ADAS
 SG_ ME_LKA_MgCntRt2_A : 50|2@0+ (1,0) [0|0] ""  ADAS
 SG_ ME_LKA_MgRt2_A_V : 48|1@0+ (1,0) [0|0] ""  ADAS

BO_ 817 SENP51: 8 SENP
 SG_ ME_LKA_CurvDervLt2 : 7|16@0+ (3.73E-009,-0.000122) [0|0] "1/meter^2"  ADAS
 SG_ ME_LKA_ViewStLt2 : 23|10@0+ (0.1,0) [0|0] "meter"  ADAS
 SG_ ME_LKA_ViewEndLt2 : 39|8@0+ (1,0) [0|0] "meter"  ADAS
 SG_ ME_LKA_WidthMkLt2 : 47|6@0+ (0.01,0) [0|0] "meter"  ADAS
 SG_ ME_LKA_MgCntLt2_B : 41|2@0+ (1,0) [0|0] ""  ADAS
 SG_ ME_LKA_LnColorLt2 : 55|3@0+ (1,0) [0|0] ""  ADAS
 SG_ ME_LKA_Pred_TypLt2 : 52|3@0+ (1,0) [0|0] ""  ADAS
 SG_ ME_LKA_MgLt2_B_V : 49|1@0+ (1,0) [0|0] ""  ADAS

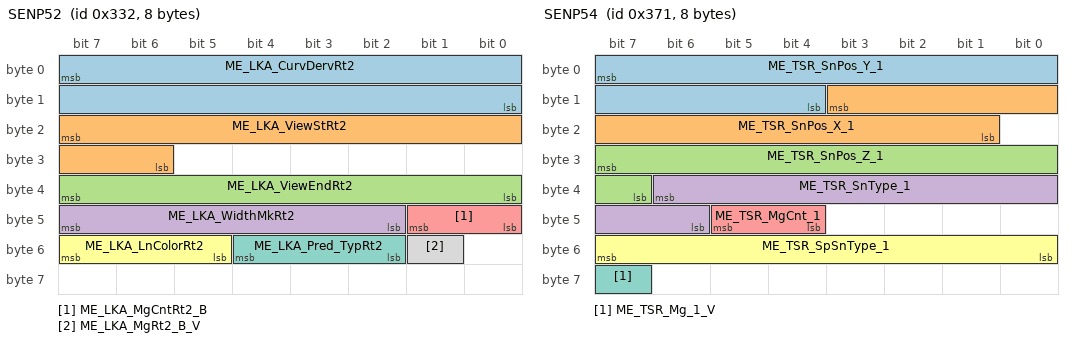
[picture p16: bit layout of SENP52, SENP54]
BO_ 818 SENP52: 8 SENP
 SG_ ME_LKA_CurvDervRt2 : 7|16@0+ (3.73E-009,-0.000122) [0|0] "1/meter^2"  ADAS
 SG_ ME_LKA_ViewStRt2 : 23|10@0+ (0.1,0) [0|0] "meter"  ADAS
 SG_ ME_LKA_ViewEndRt2 : 39|8@0+ (1,0) [0|0] "meter"  ADAS
 SG_ ME_LKA_WidthMkRt2 : 47|6@0+ (0.01,0) [0|0] "meter"  ADAS
 SG_ ME_LKA_MgCntRt2_B : 41|2@0+ (1,0) [0|0] ""  ADAS
 SG_ ME_LKA_LnColorRt2 : 55|3@0+ (1,0) [0|0] ""  ADAS
 SG_ ME_LKA_Pred_TypRt2 : 52|3@0+ (1,0) [0|0] ""  ADAS
 SG_ ME_LKA_MgRt2_B_V : 49|1@0+ (1,0) [0|0] ""  ADAS

BO_ 848 SENP26: 8 SENP
 SG_ Radar_P_Ver : 7|8@0+ (1,0) [0|0] "counter"  ADAS
 SG_ Radar_Sta : 15|8@0+ (1,0) [0|0] ""  ADAS
 SG_ Sensor_Sta_MgCnt : 23|2@0+ (1,0) [0|0] ""  ADAS
 SG_ RadarTar_HeaderCnt : 21|2@0+ (1,0) [0|0] ""  ADAS
 SG_ Radar_NumTar : 19|4@0+ (1,0) [0|0] "counter"  ADAS

BO_ 849 SENP27: 8 SENP
 SG_ RadarTar1_Pos_X : 7|12@0+ (0.125,0) [0|0] "m"  ADAS
 SG_ RadarTar1_Pos_Y : 11|12@0+ (0.125,-128) [0|0] "m"  ADAS
 SG_ RadarTar1_Vel_X : 31|12@0+ (0.1,-102) [0|0] "m/s"  ADAS
 SG_ RadarTar1_Vel_Y : 35|12@0+ (0.1,-102) [0|0] "m/s"  ADAS
 SG_ RadarTar1_ID_A : 55|8@0+ (1,0) [0|0] ""  ADAS
 SG_ RadarTar1_MgCnt_A : 57|2@0+ (1,0) [0|0] ""  ADAS

BO_ 850 SENP28: 8 SENP
 SG_ RadarTar1_Accel_X : 7|12@0+ (0.04,-40) [0|0] "m/s^2"  ADAS
 SG_ RadarTar1_ID_B : 23|8@0+ (1,0) [0|0] ""  ADAS
 SG_ RadarTar1_MeasStat : 31|3@0+ (1,0) [0|0] ""  ADAS
 SG_ RadarTar1_DynProp : 26|3@0+ (1,0) [0|0] ""  ADAS
 SG_ RadarTar1_MgCnt_B : 57|2@0+ (1,0) [0|0] ""  ADAS

BO_ 851 SENP29: 8 SENP
 SG_ RadarTar2_Pos_X : 7|12@0+ (0.125,0) [0|0] "m"  ADAS
 SG_ RadarTar2_Pos_Y : 11|12@0+ (0.125,-128) [0|0] "m"  ADAS
 SG_ RadarTar2_Vel_X : 31|12@0+ (0.1,-102) [0|0] "m/s"  ADAS
 SG_ RadarTar2_Vel_Y : 35|12@0+ (0.1,-102) [0|0] "m/s"  ADAS
 SG_ RadarTar2_ID_A : 55|8@0+ (1,0) [0|0] ""  ADAS
 SG_ RadarTar2_MgCnt_A : 57|2@0+ (1,0) [0|0] ""  ADAS

BO_ 852 SENP30: 8 SENP
 SG_ RadarTar2_Accel_X : 7|12@0+ (0.04,-40) [0|0] "m/s^2"  ADAS
 SG_ RadarTar2_ID_B : 23|8@0+ (1,0) [0|0] ""  ADAS
 SG_ RadarTar2_MeasStat : 31|3@0+ (1,0) [0|0] ""  ADAS
 SG_ RadarTar2_DynProp : 26|3@0+ (1,0) [0|0] ""  ADAS
 SG_ RadarTar2_MgCnt_B : 57|2@0+ (1,0) [0|0] ""  ADAS

BO_ 853 SENP31: 8 SENP
 SG_ RadarTar3_Pos_X : 7|12@0+ (0.125,0) [0|0] "m"  ADAS
 SG_ RadarTar3_Pos_Y : 11|12@0+ (0.125,-128) [0|0] "m"  ADAS
 SG_ RadarTar3_Vel_X : 31|12@0+ (0.1,-102) [0|0] "m/s"  ADAS
 SG_ RadarTar3_Vel_Y : 35|12@0+ (0.1,-102) [0|0] "m/s"  ADAS
 SG_ RadarTar3_ID_A : 55|8@0+ (1,0) [0|0] ""  ADAS
 SG_ RadarTar3_MgCnt_A : 57|2@0+ (1,0) [0|0] ""  ADAS

BO_ 854 SENP32: 8 SENP
 SG_ RadarTar3_Accel_X : 7|12@0+ (0.04,-40) [0|0] "m/s^2"  ADAS
 SG_ RadarTar3_ID_B : 23|8@0+ (1,0) [0|0] ""  ADAS
 SG_ RadarTar3_MeasStat : 31|3@0+ (1,0) [0|0] ""  ADAS
 SG_ RadarTar3_DynProp : 26|3@0+ (1,0) [0|0] ""  ADAS
 SG_ RadarTar3_MgCnt_B : 57|2@0+ (1,0) [0|0] ""  ADAS

BO_ 855 SENP33: 8 SENP
 SG_ RadarTar4_Pos_X : 7|12@0+ (0.125,0) [0|0] "m"  ADAS
 SG_ RadarTar4_Pos_Y : 11|12@0+ (0.125,-128) [0|0] "m"  ADAS
 SG_ RadarTar4_Vel_X : 31|12@0+ (0.1,-102) [0|0] "m/s"  ADAS
 SG_ RadarTar4_Vel_Y : 35|12@0+ (0.1,-102) [0|0] "m/s"  ADAS
 SG_ RadarTar4_ID_A : 55|8@0+ (1,0) [0|0] ""  ADAS
 SG_ RadarTar4_MgCnt_A : 57|2@0+ (1,0) [0|0] ""  ADAS

BO_ 856 SENP34: 8 SENP
 SG_ RadarTar4_Accel_X : 7|12@0+ (0.04,-40) [0|0] "m/s^2"  ADAS
 SG_ RadarTar4_ID_B : 23|8@0+ (1,0) [0|0] ""  ADAS
 SG_ RadarTar4_MeasStat : 31|3@0+ (1,0) [0|0] ""  ADAS
 SG_ RadarTar4_DynProp : 26|3@0+ (1,0) [0|0] ""  ADAS
 SG_ RadarTar4_MgCnt_B : 57|2@0+ (1,0) [0|0] ""  ADAS

BO_ 857 SENP35: 8 SENP
 SG_ RadarTar5_Pos_X : 7|12@0+ (0.125,0) [0|0] "m"  ADAS
 SG_ RadarTar5_Pos_Y : 11|12@0+ (0.125,-128) [0|0] "m"  ADAS
 SG_ RadarTar5_Vel_X : 31|12@0+ (0.1,-102) [0|0] "m/s"  ADAS
 SG_ RadarTar5_Vel_Y : 35|12@0+ (0.1,-102) [0|0] "m/s"  ADAS
 SG_ RadarTar5_ID_A : 55|8@0+ (1,0) [0|0] ""  ADAS
 SG_ RadarTar5_MgCnt_A : 57|2@0+ (1,0) [0|0] ""  ADAS

BO_ 858 SENP36: 8 SENP
 SG_ RadarTar5_Accel_X : 7|12@0+ (0.04,-40) [0|0] "m/s^2"  ADAS
 SG_ RadarTar5_ID_B : 23|8@0+ (1,0) [0|0] ""  ADAS
 SG_ RadarTar5_MeasStat : 31|3@0+ (1,0) [0|0] ""  ADAS
 SG_ RadarTar5_DynProp : 26|3@0+ (1,0) [0|0] ""  ADAS
 SG_ RadarTar5_MgCnt_B : 57|2@0+ (1,0) [0|0] ""  ADAS

BO_ 859 SENP37: 8 SENP
 SG_ RadarTar6_Pos_X : 7|12@0+ (0.125,0) [0|0] "m"  ADAS
 SG_ RadarTar6_Pos_Y : 11|12@0+ (0.125,-128) [0|0] "m"  ADAS
 SG_ RadarTar6_Vel_X : 31|12@0+ (0.1,-102) [0|0] "m/s"  ADAS
 SG_ RadarTar6_Vel_Y : 35|12@0+ (0.1,-102) [0|0] "m/s"  ADAS
 SG_ RadarTar6_ID_A : 55|8@0+ (1,0) [0|0] ""  ADAS
 SG_ RadarTar6_MgCnt_A : 57|2@0+ (1,0) [0|0] ""  ADAS

BO_ 860 SENP38: 8 SENP
 SG_ RadarTar6_Accel_X : 7|12@0+ (0.04,-40) [0|0] "m/s^2"  ADAS
 SG_ RadarTar6_ID_B : 23|8@0+ (1,0) [0|0] ""  ADAS
 SG_ RadarTar6_MeasStat : 31|3@0+ (1,0) [0|0] ""  ADAS
 SG_ RadarTar6_DynProp : 26|3@0+ (1,0) [0|0] ""  ADAS
 SG_ RadarTar6_MgCnt_B : 57|2@0+ (1,0) [0|0] ""  ADAS

BO_ 861 SENP39: 8 SENP
 SG_ RadarTar7_Pos_X : 7|12@0+ (0.125,0) [0|0] "m"  ADAS
 SG_ RadarTar7_Pos_Y : 11|12@0+ (0.125,-128) [0|0] "m"  ADAS
 SG_ RadarTar7_Vel_X : 31|12@0+ (0.1,-102) [0|0] "m/s"  ADAS
 SG_ RadarTar7_Vel_Y : 35|12@0+ (0.1,-102) [0|0] "m/s"  ADAS
 SG_ RadarTar7_ID_A : 55|8@0+ (1,0) [0|0] ""  ADAS
 SG_ RadarTar7_MgCnt_A : 57|2@0+ (1,0) [0|0] ""  ADAS

BO_ 862 SENP40: 8 SENP
 SG_ RadarTar7_Accel_X : 7|12@0+ (0.04,-40) [0|0] "m/s^2"  ADAS
 SG_ RadarTar7_ID_B : 23|8@0+ (1,0) [0|0] ""  ADAS
 SG_ RadarTar7_MeasStat : 31|3@0+ (1,0) [0|0] ""  ADAS
 SG_ RadarTar7_DynProp : 26|3@0+ (1,0) [0|0] ""  ADAS
 SG_ RadarTar7_MgCnt_B : 57|2@0+ (1,0) [0|0] ""  ADAS

BO_ 863 SENP41: 8 SENP
 SG_ RadarTar8_Pos_X : 7|12@0+ (0.125,0) [0|0] "m"  ADAS
 SG_ RadarTar8_Pos_Y : 11|12@0+ (0.125,-128) [0|0] "m"  ADAS
 SG_ RadarTar8_Vel_X : 31|12@0+ (0.1,-102) [0|0] "m/s"  ADAS
 SG_ RadarTar8_Vel_Y : 35|12@0+ (0.1,-102) [0|0] "m/s"  ADAS
 SG_ RadarTar8_ID_A : 55|8@0+ (1,0) [0|0] ""  ADAS
 SG_ RadarTar8_MgCnt_A : 57|2@0+ (1,0) [0|0] ""  ADAS

BO_ 864 SENP42: 8 SENP
 SG_ RadarTar8_Accel_X : 7|12@0+ (0.04,-40) [0|0] "m/s^2"  ADAS
 SG_ RadarTar8_ID_B : 23|8@0+ (1,0) [0|0] ""  ADAS
 SG_ RadarTar8_MeasStat : 31|3@0+ (1,0) [0|0] ""  ADAS
 SG_ RadarTar8_DynProp : 26|3@0+ (1,0) [0|0] ""  ADAS
 SG_ RadarTar8_MgCnt_B : 57|2@0+ (1,0) [0|0] ""  ADAS

BO_ 880 SENP53: 8 SENP
 SG_ ME_TSR_P_Ver : 7|8@0+ (1,0) [0|0] "counter"  ADAS
 SG_ ME_TSR_NumObs : 15|3@0+ (1,0) [0|0] "counter"  ADAS
 SG_ ME_TSR_HdMsgCnt : 12|2@0+ (1,0) [0|0] ""  ADAS
 SG_ ME_TSR_HdMsg_V : 10|1@0+ (1,0) [0|0] ""  ADAS

BO_ 881 SENP54: 8 SENP
 SG_ ME_TSR_SnPos_Y_1 : 7|12@0+ (0.1,-32) [0|0] "m"  ADAS
 SG_ ME_TSR_SnPos_X_1 : 11|11@0+ (0.1,0) [0|0] "m"  ADAS
 SG_ ME_TSR_SnPos_Z_1 : 31|9@0+ (0.1,-25.5) [0|0] "m"  ADAS
 SG_ ME_TSR_SnType_1 : 38|9@0+ (1,0) [0|0] "NA"  ADAS
 SG_ ME_TSR_MgCnt_1 : 45|2@0+ (1,0) [0|0] ""  ADAS
 SG_ ME_TSR_SpSnType_1 : 55|8@0+ (1,0) [0|0] "NA"  ADAS
 SG_ ME_TSR_Mg_1_V : 63|1@0+ (1,0) [0|0] ""  ADAS

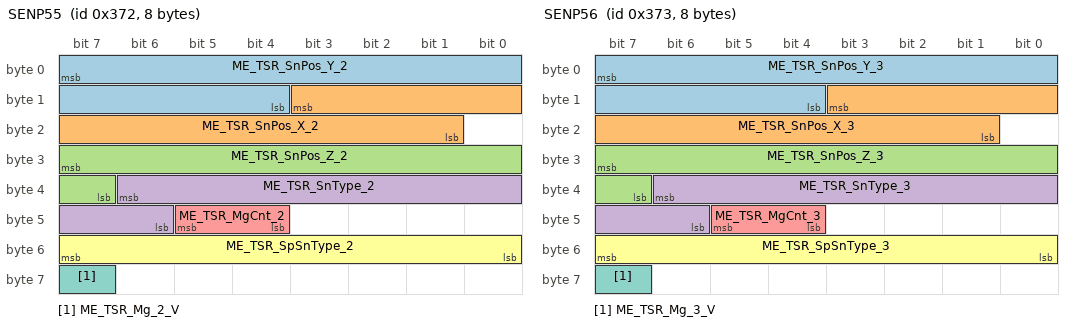
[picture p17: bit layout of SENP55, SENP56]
BO_ 882 SENP55: 8 SENP
 SG_ ME_TSR_SnPos_Y_2 : 7|12@0+ (0.1,-32) [0|0] "m"  ADAS
 SG_ ME_TSR_SnPos_X_2 : 11|11@0+ (0.1,0) [0|0] "m"  ADAS
 SG_ ME_TSR_SnPos_Z_2 : 31|9@0+ (0.1,-25.5) [0|0] "m"  ADAS
 SG_ ME_TSR_SnType_2 : 38|9@0+ (1,0) [0|0] "NA"  ADAS
 SG_ ME_TSR_MgCnt_2 : 45|2@0+ (1,0) [0|0] ""  ADAS
 SG_ ME_TSR_SpSnType_2 : 55|8@0+ (1,0) [0|0] "NA"  ADAS
 SG_ ME_TSR_Mg_2_V : 63|1@0+ (1,0) [0|0] ""  ADAS

BO_ 883 SENP56: 8 SENP
 SG_ ME_TSR_SnPos_Y_3 : 7|12@0+ (0.1,-32) [0|0] "m"  ADAS
 SG_ ME_TSR_SnPos_X_3 : 11|11@0+ (0.1,0) [0|0] "m"  ADAS
 SG_ ME_TSR_SnPos_Z_3 : 31|9@0+ (0.1,-25.5) [0|0] "m"  ADAS
 SG_ ME_TSR_SnType_3 : 38|9@0+ (1,0) [0|0] "NA"  ADAS
 SG_ ME_TSR_MgCnt_3 : 45|2@0+ (1,0) [0|0] ""  ADAS
 SG_ ME_TSR_SpSnType_3 : 55|8@0+ (1,0) [0|0] "NA"  ADAS
 SG_ ME_TSR_Mg_3_V : 63|1@0+ (1,0) [0|0] ""  ADAS

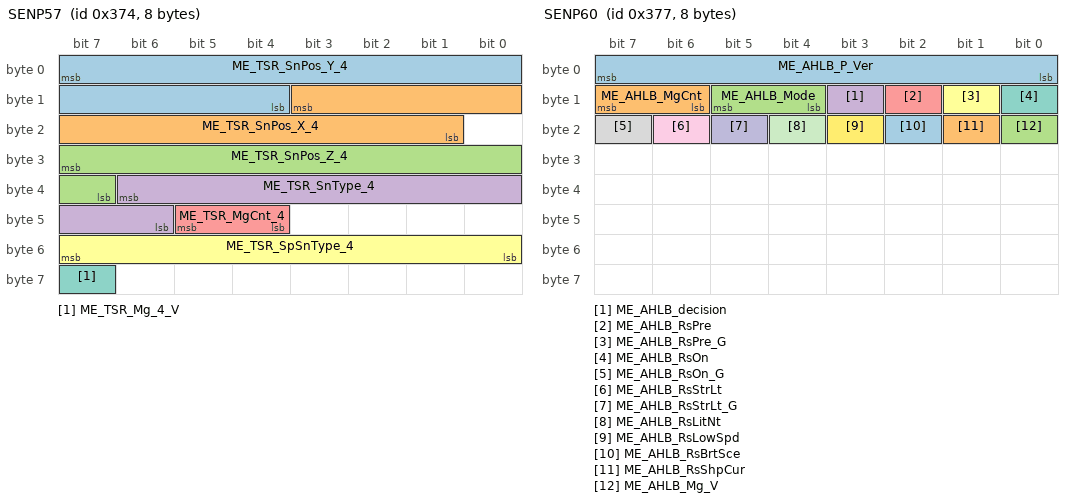
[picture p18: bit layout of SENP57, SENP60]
BO_ 884 SENP57: 8 SENP
 SG_ ME_TSR_SnPos_Y_4 : 7|12@0+ (0.1,-32) [0|0] "m"  ADAS
 SG_ ME_TSR_SnPos_X_4 : 11|11@0+ (0.1,0) [0|0] "m"  ADAS
 SG_ ME_TSR_SnPos_Z_4 : 31|9@0+ (0.1,-25.5) [0|0] "m"  ADAS
 SG_ ME_TSR_SnType_4 : 38|9@0+ (1,0) [0|0] "NA"  ADAS
 SG_ ME_TSR_MgCnt_4 : 45|2@0+ (1,0) [0|0] ""  ADAS
 SG_ ME_TSR_SpSnType_4 : 55|8@0+ (1,0) [0|0] "NA"  ADAS
 SG_ ME_TSR_Mg_4_V : 63|1@0+ (1,0) [0|0] ""  ADAS

BO_ 885 SENP58: 8 SENP
 SG_ ME_TSR_SnPos_Y_5 : 7|12@0+ (0.1,-32) [0|0] "m"  ADAS
 SG_ ME_TSR_SnPos_X_5 : 11|11@0+ (0.1,0) [0|0] "m"  ADAS
 SG_ ME_TSR_SnPos_Z_5 : 31|9@0+ (0.1,-25.5) [0|0] "m"  ADAS
 SG_ ME_TSR_SnType_5 : 38|9@0+ (1,0) [0|0] "NA"  ADAS
 SG_ ME_TSR_MgCnt_5 : 45|2@0+ (1,0) [0|0] ""  ADAS
 SG_ ME_TSR_SpSnType_5 : 55|8@0+ (1,0) [0|0] "NA"  ADAS
 SG_ ME_TSR_Mg_5_V : 63|1@0+ (1,0) [0|0] ""  ADAS

BO_ 886 SENP59: 8 SENP
 SG_ ME_TSR_SnPos_Y_6 : 7|12@0+ (0.1,-32) [0|0] "m"  ADAS
 SG_ ME_TSR_SnPos_X_6 : 11|11@0+ (0.1,0) [0|0] "m"  ADAS
 SG_ ME_TSR_SnPos_Z_6 : 31|9@0+ (0.1,-25.5) [0|0] "m"  ADAS
 SG_ ME_TSR_SnType_6 : 38|9@0+ (1,0) [0|0] "NA"  ADAS
 SG_ ME_TSR_MgCnt_6 : 45|2@0+ (1,0) [0|0] ""  ADAS
 SG_ ME_TSR_SpSnType_6 : 55|8@0+ (1,0) [0|0] "NA"  ADAS
 SG_ ME_TSR_Mg_6_V : 63|1@0+ (1,0) [0|0] ""  ADAS

BO_ 887 SENP60: 8 SENP
 SG_ ME_AHLB_P_Ver : 7|8@0+ (1,0) [0|0] "counter"  ADAS
 SG_ ME_AHLB_MgCnt : 15|2@0+ (1,0) [0|0] ""  ADAS
 SG_ ME_AHLB_Mode : 13|2@0+ (1,0) [0|0] ""  ADAS
 SG_ ME_AHLB_decision : 11|1@0+ (1,0) [0|0] ""  ADAS
 SG_ ME_AHLB_RsPre : 10|1@0+ (1,0) [0|0] ""  ADAS
 SG_ ME_AHLB_RsPre_G : 9|1@0+ (1,0) [0|0] ""  ADAS
 SG_ ME_AHLB_RsOn : 8|1@0+ (1,0) [0|0] ""  ADAS
 SG_ ME_AHLB_RsOn_G : 23|1@0+ (1,0) [0|0] ""  ADAS
 SG_ ME_AHLB_RsStrLt : 22|1@0+ (1,0) [0|0] ""  ADAS
 SG_ ME_AHLB_RsStrLt_G : 21|1@0+ (1,0) [0|0] ""  ADAS
 SG_ ME_AHLB_RsLitNt : 20|1@0+ (1,0) [0|0] ""  ADAS
 SG_ ME_AHLB_RsLowSpd : 19|1@0+ (1,0) [0|0] ""  ADAS
 SG_ ME_AHLB_RsBrtSce : 18|1@0+ (1,0) [0|0] ""  ADAS
 SG_ ME_AHLB_RsShpCur : 17|1@0+ (1,0) [0|0] ""  ADAS
 SG_ ME_AHLB_Mg_V : 16|1@0+ (1,0) [0|0] ""  ADAS

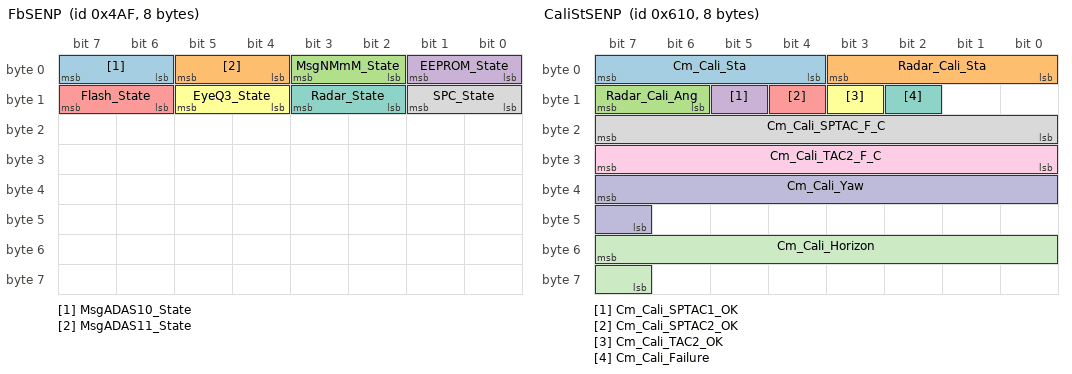
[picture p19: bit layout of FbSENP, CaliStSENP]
BO_ 1199 FbSENP: 8 SENP
 SG_ MsgADAS10_State : 7|2@0+ (1,0) [0|0] ""  ADAS
 SG_ MsgADAS11_State : 5|2@0+ (1,0) [0|0] ""  ADAS
 SG_ MsgNMmM_State : 3|2@0+ (1,0) [0|0] ""  ADAS
 SG_ EEPROM_State : 1|2@0+ (1,0) [0|0] ""  ADAS
 SG_ Flash_State : 15|2@0+ (1,0) [0|0] ""  ADAS
 SG_ EyeQ3_State : 13|2@0+ (1,0) [0|0] ""  ADAS
 SG_ Radar_State : 11|2@0+ (1,0) [0|0] ""  ADAS
 SG_ SPC_State : 9|2@0+ (1,0) [0|0] ""  ADAS

BO_ 1552 CaliStSENP: 8 SENP
 SG_ Cm_Cali_Sta : 7|4@0+ (1,0) [0|0] ""  ADAS
 SG_ Radar_Cali_Sta : 3|4@0+ (1,0) [0|0] ""  ADAS
 SG_ Radar_Cali_Ang : 15|2@0+ (1,0) [0|0] ""  ADAS
 SG_ Cm_Cali_SPTAC1_OK : 13|1@0+ (1,0) [0|0] ""  ADAS
 SG_ Cm_Cali_SPTAC2_OK : 12|1@0+ (1,0) [0|0] ""  ADAS
 SG_ Cm_Cali_TAC2_OK : 11|1@0+ (1,0) [0|0] ""  ADAS
 SG_ Cm_Cali_Failure : 10|1@0+ (1,0) [0|0] ""  ADAS
 SG_ Cm_Cali_SPTAC_F_C : 23|8@0+ (1,0) [0|0] ""  ADAS
 SG_ Cm_Cali_TAC2_F_C : 31|8@0+ (1,0) [0|0] ""  ADAS
 SG_ Cm_Cali_Yaw : 39|9@0+ (1,-248) [0|0] "pixel"  ADAS
 SG_ Cm_Cali_Horizon : 55|9@0+ (1,-160) [0|0] "pixel"  ADAS

BO_ 1809 NMmSENP: 8 SENP
 SG_ NM_SENP_Zero_Byte : 7|8@0+ (1,0) [0|0] ""  Default_Receiver
 SG_ NM_SENP_D_ES : 15|2@0+ (1,0) [0|0] ""  Default_Receiver
 SG_ NM_SENP_AR : 10|1@0+ (1,0) [0|0] ""  ADAS,ECU2,ECU3,ECU4,ECU5,ECU6,ECU7,ECU8,ECU9,ECU10,ECU11,ECU12,ECU13,ECU14,ECU15,ECU16,Tester
 SG_ NM_SENP_SC : 9|2@0+ (1,0) [0|0] ""  ADAS,ECU2,ECU3,ECU4,ECU5,ECU6,ECU7,ECU8,ECU9,ECU10,ECU11,ECU12,ECU13,ECU14,ECU15,ECU16,Tester

BO_ 1983 DiagRespFromSENP: 8 SENP
 SG_ DiagRespFromSENP : 7|64@0+ (1,0) [0|0] ""  ADAS,Tester

BO_ 1810 NMmECU2: 8 ECU2
 SG_ NM_ECU2_Zero_Byte : 7|8@0+ (1,0) [0|0] ""  Default_Receiver
 SG_ NM_ECU2_D_ES : 15|2@0+ (1,0) [0|0] ""  Default_Receiver
 SG_ NM_ECU2_AR : 10|1@0+ (1,0) [0|0] ""  ADAS,SENP,ECU3,ECU4,ECU5,ECU6,ECU7,ECU8,ECU9,ECU10,ECU11,ECU12,ECU13,ECU14,ECU15,ECU16,Tester
 SG_ NM_ECU2_SC : 9|2@0+ (1,0) [0|0] ""  ADAS,SENP,ECU3,ECU4,ECU5,ECU6,ECU7,ECU8,ECU9,ECU10,ECU11,ECU12,ECU13,ECU14,ECU15,ECU16,Tester

BO_ 1811 NMmECU3: 8 ECU3
 SG_ NM_ECU3_Zero_Byte : 7|8@0+ (1,0) [0|0] ""  Default_Receiver
 SG_ NM_ECU3_D_ES : 15|2@0+ (1,0) [0|0] ""  Default_Receiver
 SG_ NM_ECU3_AR : 10|1@0+ (1,0) [0|0] ""  ADAS,SENP,ECU2,ECU4,ECU5,ECU6,ECU7,ECU8,ECU9,ECU10,ECU11,ECU12,ECU13,ECU14,ECU15,ECU16,Tester
 SG_ NM_ECU3_SC : 9|2@0+ (1,0) [0|0] ""  ADAS,SENP,ECU2,ECU4,ECU5,ECU6,ECU7,ECU8,ECU9,ECU10,ECU11,ECU12,ECU13,ECU14,ECU15,ECU16,Tester

BO_ 1812 NMmECU4: 8 ECU4
 SG_ NM_ECU4_Zero_Byte : 7|8@0+ (1,0) [0|0] ""  Default_Receiver
 SG_ NM_ECU4_D_ES : 15|2@0+ (1,0) [0|0] ""  Default_Receiver
 SG_ NM_ECU4_AR : 10|1@0+ (1,0) [0|0] ""  ADAS,SENP,ECU2,ECU3,ECU5,ECU6,ECU7,ECU8,ECU9,ECU10,ECU11,ECU12,ECU13,ECU14,ECU15,ECU16,Tester
 SG_ NM_ECU4_SC : 9|2@0+ (1,0) [0|0] ""  ADAS,SENP,ECU2,ECU3,ECU5,ECU6,ECU7,ECU8,ECU9,ECU10,ECU11,ECU12,ECU13,ECU14,ECU15,ECU16,Tester

BO_ 1813 NMmECU5: 8 ECU5
 SG_ NM_ECU5_Zero_Byte : 7|8@0+ (1,0) [0|0] ""  Default_Receiver
 SG_ NM_ECU5_D_ES : 15|2@0+ (1,0) [0|0] ""  Default_Receiver
 SG_ NM_ECU5_AR : 10|1@0+ (1,0) [0|0] ""  ADAS,SENP,ECU2,ECU3,ECU4,ECU6,ECU7,ECU8,ECU9,ECU10,ECU11,ECU12,ECU13,ECU14,ECU15,ECU16,Tester
 SG_ NM_ECU5_SC : 9|2@0+ (1,0) [0|0] ""  ADAS,SENP,ECU2,ECU3,ECU4,ECU6,ECU7,ECU8,ECU9,ECU10,ECU11,ECU12,ECU13,ECU14,ECU15,ECU16,Tester

BO_ 1814 NMmECU6: 8 ECU6
 SG_ NM_ECU6_Zero_Byte : 7|8@0+ (1,0) [0|0] ""  Default_Receiver
 SG_ NM_ECU6_D_ES : 15|2@0+ (1,0) [0|0] ""  Default_Receiver
 SG_ NM_ECU6_AR : 10|1@0+ (1,0) [0|0] ""  ADAS,SENP,ECU2,ECU3,ECU4,ECU5,ECU7,ECU8,ECU9,ECU10,ECU11,ECU12,ECU13,ECU14,ECU15,ECU16,Tester
 SG_ NM_ECU6_SC : 9|2@0+ (1,0) [0|0] ""  ADAS,SENP,ECU2,ECU3,ECU4,ECU5,ECU7,ECU8,ECU9,ECU10,ECU11,ECU12,ECU13,ECU14,ECU15,ECU16,Tester

BO_ 1815 NMmECU7: 8 ECU7
 SG_ NM_ECU7_Zero_Byte : 7|8@0+ (1,0) [0|0] ""  Default_Receiver
 SG_ NM_ECU7_D_ES : 15|2@0+ (1,0) [0|0] ""  Default_Receiver
 SG_ NM_ECU7_AR : 10|1@0+ (1,0) [0|0] ""  ADAS,SENP,ECU2,ECU3,ECU4,ECU5,ECU6,ECU8,ECU9,ECU10,ECU11,ECU12,ECU13,ECU14,ECU15,ECU16,Tester
 SG_ NM_ECU7_SC : 9|2@0+ (1,0) [0|0] ""  ADAS,SENP,ECU2,ECU3,ECU4,ECU5,ECU6,ECU8,ECU9,ECU10,ECU11,ECU12,ECU13,ECU14,ECU15,ECU16,Tester

BO_ 1816 NMmECU8: 8 ECU8
 SG_ NM_ECU8_Zero_Byte : 7|8@0+ (1,0) [0|0] ""  Default_Receiver
 SG_ NM_ECU8_D_ES : 15|2@0+ (1,0) [0|0] ""  Default_Receiver
 SG_ NM_ECU8_AR : 10|1@0+ (1,0) [0|0] ""  ADAS,SENP,ECU2,ECU3,ECU4,ECU5,ECU6,ECU7,ECU9,ECU10,ECU11,ECU12,ECU13,ECU14,ECU15,ECU16,Tester
 SG_ NM_ECU8_SC : 9|2@0+ (1,0) [0|0] ""  ADAS,SENP,ECU2,ECU3,ECU4,ECU5,ECU6,ECU7,ECU9,ECU10,ECU11,ECU12,ECU13,ECU14,ECU15,ECU16,Tester

BO_ 1817 NMmECU9: 8 ECU9
 SG_ NM_ECU9_Zero_Byte : 7|8@0+ (1,0) [0|0] ""  Default_Receiver
 SG_ NM_ECU9_D_ES : 15|2@0+ (1,0) [0|0] ""  Default_Receiver
 SG_ NM_ECU9_AR : 10|1@0+ (1,0) [0|0] ""  ADAS,SENP,ECU2,ECU3,ECU4,ECU5,ECU6,ECU7,ECU8,ECU10,ECU11,ECU12,ECU13,ECU14,ECU15,ECU16,Tester
 SG_ NM_ECU9_SC : 9|2@0+ (1,0) [0|0] ""  ADAS,SENP,ECU2,ECU3,ECU4,ECU5,ECU6,ECU7,ECU8,ECU10,ECU11,ECU12,ECU13,ECU14,ECU15,ECU16,Tester

BO_ 1818 NMmECU10: 8 ECU10
 SG_ NM_ECU10_Zero_Byte : 7|8@0+ (1,0) [0|0] ""  Default_Receiver
 SG_ NM_ECU10_D_ES : 15|2@0+ (1,0) [0|0] ""  Default_Receiver
 SG_ NM_ECU10_AR : 10|1@0+ (1,0) [0|0] ""  ADAS,SENP,ECU2,ECU3,ECU4,ECU5,ECU6,ECU7,ECU8,ECU9,ECU11,ECU12,ECU13,ECU14,ECU15,ECU16,Tester
 SG_ NM_ECU10_SC : 9|2@0+ (1,0) [0|0] ""  ADAS,SENP,ECU2,ECU3,ECU4,ECU5,ECU6,ECU7,ECU8,ECU9,ECU11,ECU12,ECU13,ECU14,ECU15,ECU16,Tester

BO_ 1819 NMmECU11: 8 ECU11
 SG_ NM_ECU11_Zero_Byte : 7|8@0+ (1,0) [0|0] ""  Default_Receiver
 SG_ NM_ECU11_D_ES : 15|2@0+ (1,0) [0|0] ""  Default_Receiver
 SG_ NM_ECU11_AR : 10|1@0+ (1,0) [0|0] ""  ADAS,SENP,ECU2,ECU3,ECU4,ECU5,ECU6,ECU7,ECU8,ECU9,ECU10,ECU12,ECU13,ECU14,ECU15,ECU16,Tester
 SG_ NM_ECU11_SC : 9|2@0+ (1,0) [0|0] ""  ADAS,SENP,ECU2,ECU3,ECU4,ECU5,ECU6,ECU7,ECU8,ECU9,ECU10,ECU12,ECU13,ECU14,ECU15,ECU16,Tester

BO_ 1820 NMmECU12: 8 ECU12
 SG_ NM_ECU12_Zero_Byte : 7|8@0+ (1,0) [0|0] ""  Default_Receiver
 SG_ NM_ECU12_D_ES : 15|2@0+ (1,0) [0|0] ""  Default_Receiver
 SG_ NM_ECU12_AR : 10|1@0+ (1,0) [0|0] ""  ADAS,SENP,ECU2,ECU3,ECU4,ECU5,ECU6,ECU7,ECU8,ECU9,ECU10,ECU11,ECU13,ECU14,ECU15,ECU16,Tester
 SG_ NM_ECU12_SC : 9|2@0+ (1,0) [0|0] ""  ADAS,SENP,ECU2,ECU3,ECU4,ECU5,ECU6,ECU7,ECU8,ECU9,ECU10,ECU11,ECU13,ECU14,ECU15,ECU16,Tester

BO_ 1821 NMmECU13: 8 ECU13
 SG_ NM_ECU13_Zero_Byte : 7|8@0+ (1,0) [0|0] ""  Default_Receiver
 SG_ NM_ECU13_D_ES : 15|2@0+ (1,0) [0|0] ""  Default_Receiver
 SG_ NM_ECU13_AR : 10|1@0+ (1,0) [0|0] ""  ADAS,SENP,ECU2,ECU3,ECU4,ECU5,ECU6,ECU7,ECU8,ECU9,ECU10,ECU11,ECU12,ECU14,ECU15,ECU16,Tester
 SG_ NM_ECU13_SC : 9|2@0+ (1,0) [0|0] ""  ADAS,SENP,ECU2,ECU3,ECU4,ECU5,ECU6,ECU7,ECU8,ECU9,ECU10,ECU11,ECU12,ECU14,ECU15,ECU16,Tester

BO_ 1822 NMmECU14: 8 ECU14
 SG_ NM_ECU14_Zero_Byte : 7|8@0+ (1,0) [0|0] ""  Default_Receiver
 SG_ NM_ECU14_D_ES : 15|2@0+ (1,0) [0|0] ""  Default_Receiver
 SG_ NM_ECU14_AR : 10|1@0+ (1,0) [0|0] ""  ADAS,SENP,ECU2,ECU3,ECU4,ECU5,ECU6,ECU7,ECU8,ECU9,ECU10,ECU11,ECU12,ECU13,ECU15,ECU16,Tester
 SG_ NM_ECU14_SC : 9|2@0+ (1,0) [0|0] ""  ADAS,SENP,ECU2,ECU3,ECU4,ECU5,ECU6,ECU7,ECU8,ECU9,ECU10,ECU11,ECU12,ECU13,ECU15,ECU16,Tester

BO_ 1823 NMmECU15: 8 ECU15
 SG_ NM_ECU15_Zero_Byte : 7|8@0+ (1,0) [0|0] ""  Default_Receiver
 SG_ NM_ECU15_D_ES : 15|2@0+ (1,0) [0|0] ""  Default_Receiver
 SG_ NM_ECU15_AR : 10|1@0+ (1,0) [0|0] ""  ADAS,SENP,ECU2,ECU3,ECU4,ECU5,ECU6,ECU7,ECU8,ECU9,ECU10,ECU11,ECU12,ECU13,ECU14,ECU16,Tester
 SG_ NM_ECU15_SC : 9|2@0+ (1,0) [0|0] ""  ADAS,SENP,ECU2,ECU3,ECU4,ECU5,ECU6,ECU7,ECU8,ECU9,ECU10,ECU11,ECU12,ECU13,ECU14,ECU16,Tester

CM_ "Confidential Document
To 17008 20180607";
BA_DEF_ BO_  "GenMsgSendType" ENUM  "cyclicX","spontanX","cyclicIfActiveX","spontanWithDelay","cyclicAndSpontanX","cyclicAndSpontanWithDelay","spontanWithRepitition","cyclicIfActiveAndSpontanWD";
BA_DEF_ BO_  "GenMsgCycleTime" INT 0 100000;
BA_DEF_ BO_  "GenMsgDelayTime" INT 0 100000;
BA_DEF_DEF_  "GenMsgSendType" "";
BA_DEF_DEF_  "GenMsgCycleTime" 0;
BA_DEF_DEF_  "GenMsgDelayTime" 0;
BA_ "GenMsgSendType" BO_ 770 0;
BA_ "GenMsgCycleTime" BO_ 770 10;
BA_ "GenMsgSendType" BO_ 1026 4;
BA_ "GenMsgCycleTime" BO_ 1026 100;
BA_ "GenMsgSendType" BO_ 1537 1;
BA_ "GenMsgSendType" BO_ 1808 1;
BA_ "GenMsgSendType" BO_ 1919 1;
BA_ "GenMsgSendType" BO_ 2000 1;
BA_ "GenMsgSendType" BO_ 784 0;
BA_ "GenMsgCycleTime" BO_ 784 25;
BA_ "GenMsgSendType" BO_ 785 0;
BA_ "GenMsgCycleTime" BO_ 785 25;
BA_ "GenMsgSendType" BO_ 786 0;
BA_ "GenMsgCycleTime" BO_ 786 25;
BA_ "GenMsgSendType" BO_ 787 0;
BA_ "GenMsgCycleTime" BO_ 787 25;
BA_ "GenMsgSendType" BO_ 788 0;
BA_ "GenMsgCycleTime" BO_ 788 25;
BA_ "GenMsgSendType" BO_ 789 0;
BA_ "GenMsgCycleTime" BO_ 789 25;
BA_ "GenMsgSendType" BO_ 790 0;
BA_ "GenMsgCycleTime" BO_ 790 25;
BA_ "GenMsgSendType" BO_ 791 0;
BA_ "GenMsgCycleTime" BO_ 791 25;
BA_ "GenMsgSendType" BO_ 792 0;
BA_ "GenMsgCycleTime" BO_ 792 25;
BA_ "GenMsgSendType" BO_ 793 0;
BA_ "GenMsgCycleTime" BO_ 793 25;
BA_ "GenMsgSendType" BO_ 794 0;
BA_ "GenMsgCycleTime" BO_ 794 25;
BA_ "GenMsgSendType" BO_ 795 0;
BA_ "GenMsgCycleTime" BO_ 795 25;
BA_ "GenMsgSendType" BO_ 796 0;
BA_ "GenMsgCycleTime" BO_ 796 25;
BA_ "GenMsgSendType" BO_ 797 0;
BA_ "GenMsgCycleTime" BO_ 797 25;
BA_ "GenMsgSendType" BO_ 798 0;
BA_ "GenMsgCycleTime" BO_ 798 25;
BA_ "GenMsgSendType" BO_ 799 0;
BA_ "GenMsgCycleTime" BO_ 799 25;
BA_ "GenMsgSendType" BO_ 800 0;
BA_ "GenMsgCycleTime" BO_ 800 25;
BA_ "GenMsgSendType" BO_ 801 0;
BA_ "GenMsgCycleTime" BO_ 801 25;
BA_ "GenMsgSendType" BO_ 802 0;
BA_ "GenMsgCycleTime" BO_ 802 25;
BA_ "GenMsgSendType" BO_ 803 0;
BA_ "GenMsgCycleTime" BO_ 803 25;
BA_ "GenMsgSendType" BO_ 804 0;
BA_ "GenMsgCycleTime" BO_ 804 25;
BA_ "GenMsgSendType" BO_ 805 0;
BA_ "GenMsgCycleTime" BO_ 805 25;
BA_ "GenMsgSendType" BO_ 806 0;
BA_ "GenMsgCycleTime" BO_ 806 25;
BA_ "GenMsgSendType" BO_ 807 0;
BA_ "GenMsgCycleTime" BO_ 807 25;
BA_ "GenMsgSendType" BO_ 808 0;
BA_ "GenMsgCycleTime" BO_ 808 25;
BA_ "GenMsgSendType" BO_ 809 0;
BA_ "GenMsgCycleTime" BO_ 809 25;
BA_ "GenMsgSendType" BO_ 810 0;
BA_ "GenMsgCycleTime" BO_ 810 25;
BA_ "GenMsgSendType" BO_ 811 0;
BA_ "GenMsgCycleTime" BO_ 811 25;
BA_ "GenMsgSendType" BO_ 812 0;
BA_ "GenMsgCycleTime" BO_ 812 25;
BA_ "GenMsgSendType" BO_ 813 0;
BA_ "GenMsgCycleTime" BO_ 813 25;
BA_ "GenMsgSendType" BO_ 814 0;
BA_ "GenMsgCycleTime" BO_ 814 25;
BA_ "GenMsgSendType" BO_ 815 0;
BA_ "GenMsgCycleTime" BO_ 815 25;
BA_ "GenMsgSendType" BO_ 816 0;
BA_ "GenMsgCycleTime" BO_ 816 25;
BA_ "GenMsgSendType" BO_ 817 0;
BA_ "GenMsgCycleTime" BO_ 817 25;
BA_ "GenMsgSendType" BO_ 818 0;
BA_ "GenMsgCycleTime" BO_ 818 25;
BA_ "GenMsgSendType" BO_ 848 0;
BA_ "GenMsgCycleTime" BO_ 848 50;
BA_ "GenMsgSendType" BO_ 849 0;
BA_ "GenMsgCycleTime" BO_ 849 50;
BA_ "GenMsgSendType" BO_ 850 0;
BA_ "GenMsgCycleTime" BO_ 850 50;
BA_ "GenMsgSendType" BO_ 851 0;
BA_ "GenMsgCycleTime" BO_ 851 50;
BA_ "GenMsgSendType" BO_ 852 0;
BA_ "GenMsgCycleTime" BO_ 852 50;
BA_ "GenMsgSendType" BO_ 853 0;
BA_ "GenMsgCycleTime" BO_ 853 50;
BA_ "GenMsgSendType" BO_ 854 0;
BA_ "GenMsgCycleTime" BO_ 854 50;
BA_ "GenMsgSendType" BO_ 855 0;
BA_ "GenMsgCycleTime" BO_ 855 50;
BA_ "GenMsgSendType" BO_ 856 0;
BA_ "GenMsgCycleTime" BO_ 856 50;
BA_ "GenMsgSendType" BO_ 857 0;
BA_ "GenMsgCycleTime" BO_ 857 50;
BA_ "GenMsgSendType" BO_ 858 0;
BA_ "GenMsgCycleTime" BO_ 858 50;
BA_ "GenMsgSendType" BO_ 859 0;
BA_ "GenMsgCycleTime" BO_ 859 50;
BA_ "GenMsgSendType" BO_ 860 0;
BA_ "GenMsgCycleTime" BO_ 860 50;
BA_ "GenMsgSendType" BO_ 861 0;
BA_ "GenMsgCycleTime" BO_ 861 50;
BA_ "GenMsgSendType" BO_ 862 0;
BA_ "GenMsgCycleTime" BO_ 862 50;
BA_ "GenMsgSendType" BO_ 863 0;
BA_ "GenMsgCycleTime" BO_ 863 50;
BA_ "GenMsgSendType" BO_ 864 0;
BA_ "GenMsgCycleTime" BO_ 864 50;
BA_ "GenMsgSendType" BO_ 880 4;
BA_ "GenMsgCycleTime" BO_ 880 100;
BA_ "GenMsgSendType" BO_ 881 4;
BA_ "GenMsgCycleTime" BO_ 881 100;
BA_ "GenMsgSendType" BO_ 882 4;
BA_ "GenMsgCycleTime" BO_ 882 100;
BA_ "GenMsgSendType" BO_ 883 4;
BA_ "GenMsgCycleTime" BO_ 883 100;
BA_ "GenMsgSendType" BO_ 884 4;
BA_ "GenMsgCycleTime" BO_ 884 100;
BA_ "GenMsgSendType" BO_ 885 4;
BA_ "GenMsgCycleTime" BO_ 885 100;
BA_ "GenMsgSendType" BO_ 886 4;
BA_ "GenMsgCycleTime" BO_ 886 100;
BA_ "GenMsgSendType" BO_ 887 0;
BA_ "GenMsgCycleTime" BO_ 887 100;
BA_ "GenMsgSendType" BO_ 1199 4;
BA_ "GenMsgCycleTime" BO_ 1199 500;
BA_ "GenMsgSendType" BO_ 1552 1;
BA_ "GenMsgSendType" BO_ 1809 1;
BA_ "GenMsgSendType" BO_ 1983 1;
BA_ "GenMsgSendType" BO_ 1810 1;
BA_ "GenMsgSendType" BO_ 1811 1;
BA_ "GenMsgSendType" BO_ 1812 1;
BA_ "GenMsgSendType" BO_ 1813 1;
BA_ "GenMsgSendType" BO_ 1814 1;
BA_ "GenMsgSendType" BO_ 1815 1;
BA_ "GenMsgSendType" BO_ 1816 1;
BA_ "GenMsgSendType" BO_ 1817 1;
BA_ "GenMsgSendType" BO_ 1818 1;
BA_ "GenMsgSendType" BO_ 1819 1;
BA_ "GenMsgSendType" BO_ 1820 1;
BA_ "GenMsgSendType" BO_ 1821 1;
BA_ "GenMsgSendType" BO_ 1822 1;
BA_ "GenMsgSendType" BO_ 1823 1;
VAL_ 770 Brk_Sta_ADAS 0 "Inactive" 1 "Active" ;
VAL_ 770 Brk_Sta_ADAS_V 0 "Valid" 1 "Invalid" ;
VAL_ 770 YawRate_ADAS_V 0 "Valid" 1 "Invalid" ;
VAL_ 770 Str_Angle_ADAS_V 0 "Valid" 1 "Invalid" ;
VAL_ 770 CrashOpSta_ADAS 0 "No crash" 2 "Front First level" 8 "Right hand side" 16 "Left hand side" 255 "Invalid" ;
VAL_ 1026 GEAR_STA_ADAS 0 "Park/Neutral" 1 "1st" 2 "2nd" 3 "3rd" 4 "4th" 5 "5th" 6 "6th" 7 "Reverse" ;
VAL_ 1026 GEAR_STA_ADAS_V 0 "Valid" 1 "Invalid" ;
VAL_ 1026 CSW_TurnSwSta_ADAS 0 "Off" 1 "Left" 2 "Right" 3 "Invalid" ;
VAL_ 1026 FECU_LBRlySta_ADAS 0 "Off" 1 "On" 3 "invalid" ;
VAL_ 1026 FECU_HBRlySta_ADAS 0 "Off" 1 "On" 3 "invalid" ;
VAL_ 1026 LDW_Enable_ADAS 0 "Late" 1 "Medium" 2 "Early" ;
VAL_ 1026 CSW_FWipSwSta_ADAS 0 "off" 1 "Int" 2 "Low" 3 "High" 4 "Mist" 7 "Invalid" ;
VAL_ 1537 EyeQ3_Aim_Request 17 "SPTAC 1st" 18 "SPTAC 2nd" 32 "TAC2" ;
VAL_ 1808 NM_ADAS_D_ES 0 "Error Active State" 1 "Error Passive/Warning State" 2 "Bus Off State" 3 "Not used" ;
VAL_ 1808 NM_ADAS_AR 0 "No Activation Request" 1 "Activation Request" ;
VAL_ 1808 NM_ADAS_SC 0 "WU" 1 "Not Used" 2 "SA" 3 "S" ;
VAL_ 784 ME_AEB_StAFCW 39270 "No Alert" 43605 "Alert" ;
VAL_ 784 ME_AEB_StBFCV 0 "Low (stop and don't start)" 1 "Medium (continue but don't start)" 2 "High (start)" ;
VAL_ 784 ME_AEB_MgCnt 0 "counter0" 1 "counter1" 2 "counter2" 3 "counter3" ;
VAL_ 784 ME_AEB_Mg_V 0 "invalid" 1 "valid" ;
VAL_ 785 ME_PEDS_L1FCW 39270 "No Alert" 43605 "Alert" ;
VAL_ 785 ME_PEDS_L2Prfill 39270 "No Alert" 43605 "Alert" ;
VAL_ 785 ME_PEDS_L3Brking 39270 "No Alert" 43605 "Alert" ;
VAL_ 785 ME_PEDS_MgCnt 0 "counter0" 1 "counter1" 2 "counter2" 3 "counter3" ;
VAL_ 785 ME_PEDS_Mg_V 0 "invalid" 1 "valid" ;
VAL_ 786 ME_AEBSpRsStAFCW 0 "0" 65535 "65535(See AEB FCW Suppression Reason Table)" ;
VAL_ 786 ME_AEBSpRsStBFCV 0 "0" 1023 "1023(See AEB Suppression Reason Table)" ;
VAL_ 786 ME_PEDSpRsL1FCW 1 "Braking" 2 "Speed" 4 "Yaw" 8 "Reserved" 16 "Lateral Avoidance" ;
VAL_ 786 ME_AEBSpFSStAFCW 0 "Not suppressed" 1 "Suppressed due to SDM" ;
VAL_ 786 ME_PEDSpRsL2Prfill 1 "Braking" 2 "Speed" 4 "Yaw" 8 "Reserved" 16 "Lateral Avoidance" ;
VAL_ 786 ME_AEBSpFSStBFCV 0 "Not suppressed" 1 "Suppressed due to SDM" ;
VAL_ 786 ME_PEDSpFSL1FCW 0 "Not suppressed" 1 "Suppressed due to SDM" ;
VAL_ 786 ME_PEDSpFSL2Prfill 0 "Not suppressed" 1 "Suppressed due to SDM" ;
VAL_ 786 ME_PEDSpRsL3Brking 1 "Braking" 2 "Speed" 4 "Yaw" 8 "Reserved" 16 "Lateral Avoidance" ;
VAL_ 786 ME_SpRs_MgCnt 0 "counter0" 1 "counter1" 2 "counter2" 3 "counter3" ;
VAL_ 786 ME_PEDSpFSL3Brking 0 "Not suppressed" 1 "Suppressed due to SDM" ;
VAL_ 786 ME_SpRs_Mg_V 0 "invalid" 1 "valid" ;
VAL_ 787 ME_FS_Info_MgCnt 0 "counter0" 1 "counter1" 2 "counter2" 3 "counter3" ;
VAL_ 787 ME_FS_LowSun 0 "None" 1 "25" 2 "75" 3 "99" ;
VAL_ 787 ME_FS_BlurImage 0 "None" 1 "25" 2 "75" 3 "99" ;
VAL_ 787 ME_FS_FullBlock 0 "None" 1 "25" 2 "75" 3 "99" ;
VAL_ 787 ME_FS_PatialBlock 0 "None" 1 "25" 2 "75" 3 "99" ;
VAL_ 787 ME_FS_Splash 0 "None" 1 "25" 2 "75" 3 "99" ;
VAL_ 787 ME_FS_SmearSpot 0 "None" 1 "25" 2 "75" 3 "99" ;
VAL_ 787 ME_FS_SunRay 0 "None" 1 "25" 2 "75" 3 "99" ;
VAL_ 787 ME_FS_SelfGlare 0 "None" 1 "25" 2 "75" 3 "99" ;
VAL_ 787 ME_FS_FrozenWsd 0 "None" 1 "25" 2 "75" 3 "99" ;
VAL_ 787 ME_Maintenance 0 "No internal error" 1 "Internal error" ;
VAL_ 787 ME_Failsafe 0 "No  internal Failsafe" 1 "Internal Failsafe" ;
VAL_ 787 ME_FS_outOfFocus 0 "false" 1 "true" ;
VAL_ 787 ME_FS_OOCY 0 "false" 1 "true" ;
VAL_ 787 ME_FS_OOCH 0 "false" 1 "true" ;
VAL_ 787 ME_FS_TSR_OOCY 0 "false" 1 "true" ;
VAL_ 787 ME_FS_TSR_OOCP 0 "false" 1 "true" ;
VAL_ 787 ME_FS_Info_Mg_V 0 "invalid" 1 "valid" ;
VAL_ 788 ME_HeadWay_Alert 0 "No Alert" 1 "Alert" ;
VAL_ 788 ME_OBS_CutInRt 0 "No Cut In" 1 "Cut In" ;
VAL_ 788 ME_OBS_CutInLt 0 "No Cut In" 1 "Cut In" ;
VAL_ 788 ME_OBS_HdMsgCnt 0 "counter0" 1 "counter1" 2 "counter2" 3 "counter3" ;
VAL_ 788 ME_OBS_HdMsgValid 0 "invalid" 1 "valid" ;
VAL_ 789 ME_OBS_D1_MgCnt_A 0 "counter0" 1 "counter1" 2 "counter2" 3 "counter3" ;
VAL_ 789 ME_OBS_V_1 0 "invalid" 1 "valid" ;
VAL_ 790 ME_OBS_Sta_1 0 "Not Defined" 1 "Reserved" 2 "Parked" 3 "Stopped" 4 "Unknown" 5 "Moving Preceding" 6 "Stopped Oncoming" 7 "Unknown Oncoming" 8 "Moving Oncoming" ;
VAL_ 790 ME_OBS_CIPVFlag_1 0 "invalid" 1 "valid" ;
VAL_ 790 ME_OBS_Move_1 0 "Unknown" 1 "Host Cut In Left" 2 "Host Cut In Right" 3 "Host Cut Out Left" 4 "Host Cut Out Right" 5 "No cut-in/cut-out" ;
VAL_ 790 ME_OBS_BlkInfo_1 0 "invalid" 1 "off" 2 "Left on" 3 "Right on" 4 "Both" ;
VAL_ 790 ME_OBS_BrkLight_1 0 "invalid" 1 "Off" 2 "On" ;
VAL_ 790 ME_OBS_NIVFlag_1 0 "invalid" 1 "left lane" 2 "right lane" ;
VAL_ 790 ME_OBS_Type_1 0 "Unknown" 1 "Truck" 2 "Car" 3 "MotorBike" 4 "Bicycle" 5 "Pedestrians" 6 "Undecided" ;
VAL_ 790 ME_OBS_D1_MgCnt_B 0 "counter0" 1 "counter1" 2 "counter2" 3 "counter3" ;
VAL_ 790 ME_OBS_MCPFlag_1 0 "invalid" 1 "valid" ;
VAL_ 791 ME_OBS_D2_MgCnt_A 0 "counter0" 1 "counter1" 2 "counter2" 3 "counter3" ;
VAL_ 791 ME_OBS_V_2 0 "invalid" 1 "valid" ;
VAL_ 792 ME_OBS_Sta_2 0 "Not Defined" 1 "Reserved" 2 "Parked" 3 "Stopped" 4 "Unknown" 5 "Moving Preceding" 6 "Stopped Oncoming" 7 "Unknown Oncoming" 8 "Moving Oncoming" ;
VAL_ 792 ME_OBS_CIPVFlag_2 0 "invalid" 1 "valid" ;
VAL_ 792 ME_OBS_Move_2 0 "Unknown" 1 "Host Cut In Left" 2 "Host Cut In Right" 3 "Host Cut Out Left" 4 "Host Cut Out Right" 5 "No cut-in/cut-out" ;
VAL_ 792 ME_OBS_BlkInfo_2 0 "invalid" 1 "off" 2 "Left on" 3 "Right on" 4 "Both" ;
VAL_ 792 ME_OBS_BrkLight_2 0 "invalid" 1 "Off" 2 "On" ;
VAL_ 792 ME_OBS_NIVFlag_2 0 "invalid" 1 "left lane" 2 "right lane" ;
VAL_ 792 ME_OBS_Type_2 0 "Unknown" 1 "Truck" 2 "Car" 3 "MotorBike" 4 "Bicycle" 5 "Pedestrians" 6 "Undecided" ;
VAL_ 792 ME_OBS_D2_MgCnt_B 0 "counter0" 1 "counter1" 2 "counter2" 3 "counter3" ;
VAL_ 792 ME_OBS_MCPFlag_2 0 "invalid" 1 "valid" ;
VAL_ 793 ME_OBS_D3_MgCnt_A 0 "counter0" 1 "counter1" 2 "counter2" 3 "counter3" ;
VAL_ 793 ME_OBS_V_3 0 "invalid" 1 "valid" ;
VAL_ 794 ME_OBS_Sta_3 0 "Not Defined" 1 "Reserved" 2 "Parked" 3 "Stopped" 4 "Unknown" 5 "Moving Preceding" 6 "Stopped Oncoming" 7 "Unknown Oncoming" 8 "Moving Oncoming" ;
VAL_ 794 ME_OBS_CIPVFlag_3 0 "invalid" 1 "valid" ;
VAL_ 794 ME_OBS_Move_3 0 "Unknown" 1 "Host Cut In Left" 2 "Host Cut In Right" 3 "Host Cut Out Left" 4 "Host Cut Out Right" 5 "No cut-in/cut-out" ;
VAL_ 794 ME_OBS_BlkInfo_3 0 "invalid" 1 "off" 2 "Left on" 3 "Right on" 4 "Both" ;
VAL_ 794 ME_OBS_BrkLight_3 0 "invalid" 1 "Off" 2 "On" ;
VAL_ 794 ME_OBS_NIVFlag_3 0 "invalid" 1 "left lane" 2 "right lane" ;
VAL_ 794 ME_OBS_Type_3 0 "Unknown" 1 "Truck" 2 "Car" 3 "MotorBike" 4 "Bicycle" 5 "Pedestrians" 6 "Undecided" ;
VAL_ 794 ME_OBS_D3_MgCnt_B 0 "counter0" 1 "counter1" 2 "counter2" 3 "counter3" ;
VAL_ 794 ME_OBS_MCPFlag_3 0 "invalid" 1 "valid" ;
VAL_ 795 ME_OBS_D4_MgCnt_A 0 "counter0" 1 "counter1" 2 "counter2" 3 "counter3" ;
VAL_ 795 ME_OBS_V_4 0 "invalid" 1 "valid" ;
VAL_ 796 ME_OBS_Sta_4 0 "Not Defined" 1 "Reserved" 2 "Parked" 3 "Stopped" 4 "Unknown" 5 "Moving Preceding" 6 "Stopped Oncoming" 7 "Unknown Oncoming" 8 "Moving Oncoming" ;
VAL_ 796 ME_OBS_CIPVFlag_4 0 "invalid" 1 "valid" ;
VAL_ 796 ME_OBS_Move_4 0 "Unknown" 1 "Host Cut In Left" 2 "Host Cut In Right" 3 "Host Cut Out Left" 4 "Host Cut Out Right" 5 "No cut-in/cut-out" ;
VAL_ 796 ME_OBS_BlkInfo_4 0 "invalid" 1 "off" 2 "Left on" 3 "Right on" 4 "Both" ;
VAL_ 796 ME_OBS_BrkLight_4 0 "invalid" 1 "Off" 2 "On" ;
VAL_ 796 ME_OBS_NIVFlag_4 0 "invalid" 1 "left lane" 2 "right lane" ;
VAL_ 796 ME_OBS_Type_4 0 "Unknown" 1 "Truck" 2 "Car" 3 "MotorBike" 4 "Bicycle" 5 "Pedestrians" 6 "Undecided" ;
VAL_ 796 ME_OBS_D4_MgCnt_B 0 "counter0" 1 "counter1" 2 "counter2" 3 "counter3" ;
VAL_ 796 ME_OBS_MCPFlag_4 0 "invalid" 1 "valid" ;
VAL_ 797 ME_OBS_D5_MgCnt_A 0 "counter0" 1 "counter1" 2 "counter2" 3 "counter3" ;
VAL_ 797 ME_OBS_V_5 0 "invalid" 1 "valid" ;
VAL_ 798 ME_OBS_Sta_5 0 "Not Defined" 1 "Reserved" 2 "Parked" 3 "Stopped" 4 "Unknown" 5 "Moving Preceding" 6 "Stopped Oncoming" 7 "Unknown Oncoming" 8 "Moving Oncoming" ;
VAL_ 798 ME_OBS_CIPVFlag_5 0 "invalid" 1 "valid" ;
VAL_ 798 ME_OBS_Move_5 0 "Unknown" 1 "Host Cut In Left" 2 "Host Cut In Right" 3 "Host Cut Out Left" 4 "Host Cut Out Right" 5 "No cut-in/cut-out" ;
VAL_ 798 ME_OBS_BlkInfo_5 0 "invalid" 1 "off" 2 "Left on" 3 "Right on" 4 "Both" ;
VAL_ 798 ME_OBS_BrkLight_5 0 "invalid" 1 "Off" 2 "On" ;
VAL_ 798 ME_OBS_NIVFlag_5 0 "invalid" 1 "left lane" 2 "right lane" ;
VAL_ 798 ME_OBS_Type_5 0 "Unknown" 1 "Truck" 2 "Car" 3 "MotorBike" 4 "Bicycle" 5 "Pedestrians" 6 "Undecided" ;
VAL_ 798 ME_OBS_D5_MgCnt_B 0 "counter0" 1 "counter1" 2 "counter2" 3 "counter3" ;
VAL_ 798 ME_OBS_MCPFlag_5 0 "invalid" 1 "valid" ;
VAL_ 799 ME_OBS_D6_MgCnt_A 0 "counter0" 1 "counter1" 2 "counter2" 3 "counter3" ;
VAL_ 799 ME_OBS_V_6 0 "invalid" 1 "valid" ;
VAL_ 800 ME_OBS_Sta_6 0 "Not Defined" 1 "Reserved" 2 "Parked" 3 "Stopped" 4 "Unknown" 5 "Moving Preceding" 6 "Stopped Oncoming" 7 "Unknown Oncoming" 8 "Moving Oncoming" ;
VAL_ 800 ME_OBS_CIPVFlag_6 0 "invalid" 1 "valid" ;
VAL_ 800 ME_OBS_Move_6 0 "Unknown" 1 "Host Cut In Left" 2 "Host Cut In Right" 3 "Host Cut Out Left" 4 "Host Cut Out Right" 5 "No cut-in/cut-out" ;
VAL_ 800 ME_OBS_BlkInfo_6 0 "invalid" 1 "off" 2 "Left on" 3 "Right on" 4 "Both" ;
VAL_ 800 ME_OBS_BrkLight_6 0 "invalid" 1 "Off" 2 "On" ;
VAL_ 800 ME_OBS_NIVFlag_6 0 "invalid" 1 "left lane" 2 "right lane" ;
VAL_ 800 ME_OBS_Type_6 0 "Unknown" 1 "Truck" 2 "Car" 3 "MotorBike" 4 "Bicycle" 5 "Pedestrians" 6 "Undecided" ;
VAL_ 800 ME_OBS_D6_MgCnt_B 0 "counter0" 1 "counter1" 2 "counter2" 3 "counter3" ;
VAL_ 800 ME_OBS_MCPFlag_6 0 "invalid" 1 "valid" ;
VAL_ 801 ME_OBS_D7_MgCnt_A 0 "counter0" 1 "counter1" 2 "counter2" 3 "counter3" ;
VAL_ 801 ME_OBS_V_7 0 "invalid" 1 "valid" ;
VAL_ 802 ME_OBS_Sta_7 0 "Not Defined" 1 "Reserved" 2 "Parked" 3 "Stopped" 4 "Unknown" 5 "Moving Preceding" 6 "Stopped Oncoming" 7 "Unknown Oncoming" 8 "Moving Oncoming" ;
VAL_ 802 ME_OBS_CIPVFlag_7 0 "invalid" 1 "valid" ;
VAL_ 802 ME_OBS_Move_7 0 "Unknown" 1 "Host Cut In Left" 2 "Host Cut In Right" 3 "Host Cut Out Left" 4 "Host Cut Out Right" 5 "No cut-in/cut-out" ;
VAL_ 802 ME_OBS_BlkInfo_7 0 "invalid" 1 "off" 2 "Left on" 3 "Right on" 4 "Both" ;
VAL_ 802 ME_OBS_BrkLight_7 0 "invalid" 1 "Off" 2 "On" ;
VAL_ 802 ME_OBS_NIVFlag_7 0 "invalid" 1 "left lane" 2 "right lane" ;
VAL_ 802 ME_OBS_Type_7 0 "Unknown" 1 "Truck" 2 "Car" 3 "MotorBike" 4 "Bicycle" 5 "Pedestrians" 6 "Undecided" ;
VAL_ 802 ME_OBS_D7_MgCnt_B 0 "counter0" 1 "counter1" 2 "counter2" 3 "counter3" ;
VAL_ 802 ME_OBS_MCPFlag_7 0 "invalid" 1 "valid" ;
VAL_ 803 ME_OBS_D8_MgCnt_A 0 "counter0" 1 "counter1" 2 "counter2" 3 "counter3" ;
VAL_ 803 ME_OBS_V_8 0 "invalid" 1 "valid" ;
VAL_ 804 ME_OBS_Sta_8 0 "Not Defined" 1 "Reserved" 2 "Parked" 3 "Stopped" 4 "Unknown" 5 "Moving Preceding" 6 "Stopped Oncoming" 7 "Unknown Oncoming" 8 "Moving Oncoming" ;
VAL_ 804 ME_OBS_CIPVFlag_8 0 "invalid" 1 "valid" ;
VAL_ 804 ME_OBS_Move_8 0 "Unknown" 1 "Host Cut In Left" 2 "Host Cut In Right" 3 "Host Cut Out Left" 4 "Host Cut Out Right" 5 "No cut-in/cut-out" ;
VAL_ 804 ME_OBS_BlkInfo_8 0 "invalid" 1 "off" 2 "Left on" 3 "Right on" 4 "Both" ;
VAL_ 804 ME_OBS_BrkLight_8 0 "invalid" 1 "Off" 2 "On" ;
VAL_ 804 ME_OBS_NIVFlag_8 0 "invalid" 1 "left lane" 2 "right lane" ;
VAL_ 804 ME_OBS_Type_8 0 "Unknown" 1 "Truck" 2 "Car" 3 "MotorBike" 4 "Bicycle" 5 "Pedestrians" 6 "Undecided" ;
VAL_ 804 ME_OBS_D8_MgCnt_B 0 "counter0" 1 "counter1" 2 "counter2" 3 "counter3" ;
VAL_ 804 ME_OBS_MCPFlag_8 0 "invalid" 1 "valid" ;
VAL_ 805 ME_OBS_D9_MgCnt_A 0 "counter0" 1 "counter1" 2 "counter2" 3 "counter3" ;
VAL_ 805 ME_OBS_V_9 0 "invalid" 1 "valid" ;
VAL_ 806 ME_OBS_Sta_9 0 "Not Defined" 1 "Reserved" 2 "Parked" 3 "Stopped" 4 "Unknown" 5 "Moving Preceding" 6 "Stopped Oncoming" 7 "Unknown Oncoming" 8 "Moving Oncoming" ;
VAL_ 806 ME_OBS_CIPVFlag_9 0 "invalid" 1 "valid" ;
VAL_ 806 ME_OBS_Move_9 0 "Unknown" 1 "Host Cut In Left" 2 "Host Cut In Right" 3 "Host Cut Out Left" 4 "Host Cut Out Right" 5 "No cut-in/cut-out" ;
VAL_ 806 ME_OBS_BlkInfo_9 0 "invalid" 1 "off" 2 "Left on" 3 "Right on" 4 "Both" ;
VAL_ 806 ME_OBS_BrkLight_9 0 "invalid" 1 "Off" 2 "On" ;
VAL_ 806 ME_OBS_NIVFlag_9 0 "invalid" 1 "left lane" 2 "right lane" ;
VAL_ 806 ME_OBS_Type_9 0 "Unknown" 1 "Truck" 2 "Car" 3 "MotorBike" 4 "Bicycle" 5 "Pedestrians" 6 "Undecided" ;
VAL_ 806 ME_OBS_D9_MgCnt_B 0 "counter0" 1 "counter1" 2 "counter2" 3 "counter3" ;
VAL_ 806 ME_OBS_MCPFlag_9 0 "invalid" 1 "valid" ;
VAL_ 807 ME_OBS_D10_MgCnt_A 0 "counter0" 1 "counter1" 2 "counter2" 3 "counter3" ;
VAL_ 807 ME_OBS_V_10 0 "invalid" 1 "valid" ;
VAL_ 808 ME_OBS_Sta_10 0 "Not Defined" 1 "Reserved" 2 "Parked" 3 "Stopped" 4 "Unknown" 5 "Moving Preceding" 6 "Stopped Oncoming" 7 "Unknown Oncoming" 8 "Moving Oncoming" ;
VAL_ 808 ME_OBS_CIPVFlag_10 0 "invalid" 1 "valid" ;
VAL_ 808 ME_OBS_Move_10 0 "Unknown" 1 "Host Cut In Left" 2 "Host Cut In Right" 3 "Host Cut Out Left" 4 "Host Cut Out Right" 5 "No cut-in/cut-out" ;
VAL_ 808 ME_OBS_BlkInfo_10 0 "invalid" 1 "off" 2 "Left on" 3 "Right on" 4 "Both" ;
VAL_ 808 ME_OBS_BrkLight_10 0 "invalid" 1 "Off" 2 "On" ;
VAL_ 808 ME_OBS_NIVFlag_10 0 "invalid" 1 "left lane" 2 "right lane" ;
VAL_ 808 ME_OBS_Type_10 0 "Unknown" 1 "Truck" 2 "Car" 3 "MotorBike" 4 "Bicycle" 5 "Pedestrians" 6 "Undecided" ;
VAL_ 808 ME_OBS_D10_MgCnt_B 0 "counter0" 1 "counter1" 2 "counter2" 3 "counter3" ;
VAL_ 808 ME_OBS_MCPFlag_10 0 "invalid" 1 "valid" ;
VAL_ 809 ME_LDW_LtLn_V 0 "Not Valid" 1 "Valid" ;
VAL_ 809 ME_LDW_LnRt_V 0 "Not Valid" 1 "Valid" ;
VAL_ 809 ME_LDW_RTA 0 "Not Valid" 1 "Valid" ;
VAL_ 809 ME_LDW_NA_RsSpeed 0 "no reason" 1 "speed condition not met" ;
VAL_ 809 ME_LDW_NA_RsSingle 0 "no reason" 1 "single_side_availability is FALSE and one or more lines are missing" ;
VAL_ 809 ME_LDW_NA_RsNarrow 0 "no reason" 1 "lane width condition not met" ;
VAL_ 809 ME_LDW_RsStr 0 "no reason" 1 "steering wheel rate above threshold" ;
VAL_ 809 ME_LDW_RsBlink_R 0 "no reason" 1 "right  turn signal active" ;
VAL_ 809 ME_LDW_RsBlink_L 0 "no reason" 1 "left  turn signal active" ;
VAL_ 809 ME_LDW_RsBrake 0 "no reason" 1 "brake" ;
VAL_ 809 ME_LDW_RsAccel 0 "no reason" 1 "acceleration" ;
VAL_ 809 ME_LDW_RsGen 0 "no reason" 1 "generic suppression" ;
VAL_ 809 ME_LDW_MgCnt 0 "counter0" 1 "counter1" 2 "counter2" 3 "counter3" ;
VAL_ 809 ME_LDW_Sta_L 0 "Warning Suppressed" 1 "Warning Enabled" 2 "Warning Active" ;
VAL_ 809 ME_LDW_Sta_R 0 "Warning Suppressed" 1 "Warning Enabled" 2 "Warning Active" ;
VAL_ 809 ME_LDW_Mg_V 0 "invalid" 1 "valid" ;
VAL_ 810 ME_LKA_HLnWidth_V 0 "false" 1 "true" ;
VAL_ 810 ME_LKA_RdType 0 "Unknown" 1 "Highway" ;
VAL_ 810 ME_LKA_Construct 0 "false" 1 "true" ;
VAL_ 810 ME_LKA_HWER 0 "false" 1 "true" ;
VAL_ 810 ME_LKA_HWEL 0 "false" 1 "true" ;
VAL_ 810 ME_LKA_MgRt 0 "false" 1 "true" ;
VAL_ 810 ME_LKA_HdMsgCnt 0 "counter0" 1 "counter1" 2 "counter2" 3 "counter3" ;
VAL_ 810 ME_LKA_MgLt 0 "false" 1 "true" ;
VAL_ 810 ME_LKA_HdMsg_V 0 "invalid" 1 "valid" ;
VAL_ 811 ME_LKA_LnTypLt 0 "Dashed" 1 "Solid" 2 "Undecided" 3 "Road Edge" 4 "Double Line" 5 "Botts Dots" 6 "Barrier" ;
VAL_ 811 ME_LKA_QtyLt 0 "Very Low Quality" 1 "Low Quality" 2 "Prediction" 3 "High Quality" ;
VAL_ 811 ME_LKA_MgCntLt_A 0 "counter0" 1 "counter1" 2 "counter2" 3 "counter3" ;
VAL_ 811 ME_LKA_MgLt_A_V 0 "invalid" 1 "valid" ;
VAL_ 812 ME_LKA_LnTypRt 0 "Dashed" 1 "Solid" 2 "Undecided" 3 "Road Edge" 4 "Double Line" 5 "Botts Dots" 6 "Barrier" ;
VAL_ 812 ME_LKA_QtyRt 0 "Very Low Quality" 1 "Low Quality" 2 "Prediction" 3 "High Quality" ;
VAL_ 812 ME_LKA_MgCntRt_A 0 "counter0" 1 "counter1" 2 "counter2" 3 "counter3" ;
VAL_ 812 ME_LKA_MgRt_A_V 0 "invalid" 1 "valid" ;
VAL_ 813 ME_LKA_LnCrossLt 0 "No lane change" 1 "Left lane change" ;
VAL_ 813 ME_LKA_MgCntLt_B 0 "counter0" 1 "counter1" 2 "counter2" 3 "counter3" ;
VAL_ 813 ME_LKA_LnColorLt 0 "Unknown" 1 "White" 2 "Yellow/Orange/Red" 3 "Blue/Green" ;
VAL_ 813 ME_LKA_Pred_TypLt 0 "Not Predicted" 1 "Diverging Prediction" 2 "Guard Rail Shadow Prediction" 3 "Other Side Based Prediction" 4 "Merge Prediction" 5 "Occluded Lane Mark Extrapolation" 6 "Headway Extrapolation" ;
VAL_ 813 ME_LKA_MgLt_B_V 0 "invalid" 1 "valid" ;
VAL_ 814 ME_LKA_LnCrossRt 0 "No lane change" 1 "Right lane change" ;
VAL_ 814 ME_LKA_MgCntRt_B 0 "counter0" 1 "counter1" 2 "counter2" 3 "counter3" ;
VAL_ 814 ME_LKA_LnColorRt 0 "Unknown" 1 "White" 2 "Yellow/Orange/Red" 3 "Blue/Green" ;
VAL_ 814 ME_LKA_Pre_TypRt 0 "Not Predicted" 1 "Diverging Prediction" 2 "Guard Rail Shadow Prediction" 3 "Other Side Based Prediction" 4 "Merge Prediction" 5 "Occluded Lane Mark Extrapolation" 6 "Headway Extrapolation" ;
VAL_ 814 ME_LKA_MgRt_B_V 0 "invalid" 1 "valid" ;
VAL_ 815 ME_LKA_LnTypLt2 0 "Dashed" 1 "Solid" 2 "Undecided" 3 "Road Edge" 4 "Double Line" 5 "Botts Dots" 6 "Barrier" ;
VAL_ 815 ME_LKA_QtyLt2 0 "Very Low Quality" 1 "Low Quality" 2 "Prediction" 3 "High Quality" ;
VAL_ 815 ME_LKA_MgCntLt2_A 0 "counter0" 1 "counter1" 2 "counter2" 3 "counter3" ;
VAL_ 815 ME_LKA_MgLt2_A_V 0 "invalid" 1 "valid" ;
VAL_ 816 ME_LKA_LnTypRt2 0 "Dashed" 1 "Solid" 2 "Undecided" 3 "Road Edge" 4 "Double Line" 5 "Botts Dots" 6 "Barrier" ;
VAL_ 816 ME_LKA_QtyRt2 0 "Very Low Quality" 1 "Low Quality" 2 "Prediction" 3 "High Quality" ;
VAL_ 816 ME_LKA_MgCntRt2_A 0 "counter0" 1 "counter1" 2 "counter2" 3 "counter3" ;
VAL_ 816 ME_LKA_MgRt2_A_V 0 "invalid" 1 "valid" ;
VAL_ 817 ME_LKA_MgCntLt2_B 0 "counter0" 1 "counter1" 2 "counter2" 3 "counter3" ;
VAL_ 817 ME_LKA_LnColorLt2 0 "Unknown" 1 "White" 2 "Yellow/Orange/Red" 3 "Blue/Green" ;
VAL_ 817 ME_LKA_Pred_TypLt2 0 "Not Predicted" 1 "Diverging Prediction" 2 "Guard Rail Shadow Prediction" 3 "Other Side Based Prediction" 4 "Merge Prediction" 5 "Occluded Lane Mark Extrapolation" 6 "Headway Extrapolation" ;
VAL_ 817 ME_LKA_MgLt2_B_V 0 "invalid" 1 "valid" ;
VAL_ 818 ME_LKA_MgCntRt2_B 0 "counter0" 1 "counter1" 2 "counter2" 3 "counter3" ;
VAL_ 818 ME_LKA_LnColorRt2 0 "Unknown" 1 "White" 2 "Yellow/Orange/Red" 3 "Blue/Green" ;
VAL_ 818 ME_LKA_Pred_TypRt2 0 "Not Predicted" 1 "Diverging Prediction" 2 "Guard Rail Shadow Prediction" 3 "Other Side Based Prediction" 4 "Merge Prediction" 5 "Occluded Lane Mark Extrapolation" 6 "Headway Extrapolation" ;
VAL_ 818 ME_LKA_MgRt2_B_V 0 "invalid" 1 "valid" ;
VAL_ 848 Radar_Sta 0 "Normal" 1 "Low sensitivity" 2 "Radar Fault" 4 "CAN abnormal" 8 "Voltage Abnormal" 16 "Diagnosis Signal" 128 "Invalid" ;
VAL_ 848 Sensor_Sta_MgCnt 0 "counter0" 1 "counter1" 2 "counter2" 3 "counter3" ;
VAL_ 848 RadarTar_HeaderCnt 0 "counter0" 1 "counter1" 2 "counter2" 3 "counter3" ;
VAL_ 849 RadarTar1_ID_A 0 "No Object" 1 "1" 2 "2" 3 "3" 99 "99" 128 "Invalid" ;
VAL_ 849 RadarTar1_MgCnt_A 0 "counter0" 1 "counter1" 2 "counter2" 3 "counter3" ;
VAL_ 850 RadarTar1_ID_B 0 "No Object" 1 "1" 2 "2" 3 "3" 99 "99" 128 "Invalid" ;
VAL_ 850 RadarTar1_MeasStat 0 "no onject" 1 "object predicted" 2 "object measured" 4 "Invalid" ;
VAL_ 850 RadarTar1_DynProp 0 "unclassified" 1 "stopped" 2 "moving" 4 "Invalid" ;
VAL_ 850 RadarTar1_MgCnt_B 0 "counter0" 1 "counter1" 2 "counter2" 3 "counter3" ;
VAL_ 851 RadarTar2_ID_A 0 "No Object" 1 "1" 2 "2" 3 "3" 99 "99" 128 "Invalid" ;
VAL_ 851 RadarTar2_MgCnt_A 0 "counter0" 1 "counter1" 2 "counter2" 3 "counter3" ;
VAL_ 852 RadarTar2_ID_B 0 "No Object" 1 "1" 2 "2" 3 "3" 99 "99" 128 "Invalid" ;
VAL_ 852 RadarTar2_MeasStat 0 "No onject" 1 "Object predicted" 2 "Object measured" 4 "Invalid" ;
VAL_ 852 RadarTar2_DynProp 0 "Unclassified" 1 "Stopped" 2 "Moving" 4 "Invalid" ;
VAL_ 852 RadarTar2_MgCnt_B 0 "counter0" 1 "counter1" 2 "counter2" 3 "counter3" ;
VAL_ 853 RadarTar3_ID_A 0 "No Object" 1 "1" 2 "2" 3 "3" 99 "99" 128 "Invalid" ;
VAL_ 853 RadarTar3_MgCnt_A 0 "counter0" 1 "counter1" 2 "counter2" 3 "counter3" ;
VAL_ 854 RadarTar3_ID_B 0 "No Object" 1 "1" 2 "2" 3 "3" 99 "99" 128 "Invalid" ;
VAL_ 854 RadarTar3_MeasStat 0 "No onject" 1 "Object predicted" 2 "Object measured" 4 "Invalid" ;
VAL_ 854 RadarTar3_DynProp 0 "Unclassified" 1 "Stopped" 2 "Moving" 4 "Invalid" ;
VAL_ 854 RadarTar3_MgCnt_B 0 "counter0" 1 "counter1" 2 "counter2" 3 "counter3" ;
VAL_ 855 RadarTar4_ID_A 0 "No Object" 1 "1" 2 "2" 3 "3" 99 "99" 128 "Invalid" ;
VAL_ 855 RadarTar4_MgCnt_A 0 "counter0" 1 "counter1" 2 "counter2" 3 "counter3" ;
VAL_ 856 RadarTar4_ID_B 0 "No Object" 1 "1" 2 "2" 3 "3" 99 "99" 128 "Invalid" ;
VAL_ 856 RadarTar4_MeasStat 0 "No onject" 1 "Object predicted" 2 "Object measured" 4 "Invalid" ;
VAL_ 856 RadarTar4_DynProp 0 "Unclassified" 1 "Stopped" 2 "Moving" 4 "Invalid" ;
VAL_ 856 RadarTar4_MgCnt_B 0 "counter0" 1 "counter1" 2 "counter2" 3 "counter3" ;
VAL_ 857 RadarTar5_ID_A 0 "No Object" 1 "1" 2 "2" 3 "3" 99 "99" 128 "Invalid" ;
VAL_ 857 RadarTar5_MgCnt_A 0 "counter0" 1 "counter1" 2 "counter2" 3 "counter3" ;
VAL_ 858 RadarTar5_ID_B 0 "No Object" 1 "1" 2 "2" 3 "3" 99 "99" 128 "Invalid" ;
VAL_ 858 RadarTar5_MeasStat 0 "No onject" 1 "Object predicted" 2 "Object measured" 4 "Invalid" ;
VAL_ 858 RadarTar5_DynProp 0 "Unclassified" 1 "Stopped" 2 "Moving" 4 "Invalid" ;
VAL_ 858 RadarTar5_MgCnt_B 0 "counter0" 1 "counter1" 2 "counter2" 3 "counter3" ;
VAL_ 859 RadarTar6_ID_A 0 "No Object" 1 "1" 2 "2" 3 "3" 99 "99" 128 "Invalid" ;
VAL_ 859 RadarTar6_MgCnt_A 0 "counter0" 1 "counter1" 2 "counter2" 3 "counter3" ;
VAL_ 860 RadarTar6_ID_B 0 "No Object" 1 "1" 2 "2" 3 "3" 99 "99" 128 "Invalid" ;
VAL_ 860 RadarTar6_MeasStat 0 "No onject" 1 "Object predicted" 2 "Object measured" 4 "Invalid" ;
VAL_ 860 RadarTar6_DynProp 0 "Unclassified" 1 "Stopped" 2 "Moving" 4 "Invalid" ;
VAL_ 860 RadarTar6_MgCnt_B 0 "counter0" 1 "counter1" 2 "counter2" 3 "counter3" ;
VAL_ 861 RadarTar7_ID_A 0 "No Object" 1 "1" 2 "2" 3 "3" 99 "99" 128 "Invalid" ;
VAL_ 861 RadarTar7_MgCnt_A 0 "counter0" 1 "counter1" 2 "counter2" 3 "counter3" ;
VAL_ 862 RadarTar7_ID_B 0 "No Object" 1 "1" 2 "2" 3 "3" 99 "99" 128 "Invalid" ;
VAL_ 862 RadarTar7_MeasStat 0 "No onject" 1 "Object predicted" 2 "Object measured" 4 "Invalid" ;
VAL_ 862 RadarTar7_DynProp 0 "Unclassified" 1 "Stopped" 2 "Moving" 4 "Invalid" ;
VAL_ 862 RadarTar7_MgCnt_B 0 "counter0" 1 "counter1" 2 "counter2" 3 "counter3" ;
VAL_ 863 RadarTar8_ID_A 0 "No Object" 1 "1" 2 "2" 3 "3" 99 "99" 128 "Invalid" ;
VAL_ 863 RadarTar8_MgCnt_A 0 "counter0" 1 "counter1" 2 "counter2" 3 "counter3" ;
VAL_ 864 RadarTar8_ID_B 0 "No Object" 1 "1" 2 "2" 3 "3" 99 "99" 128 "Invalid" ;
VAL_ 864 RadarTar8_MeasStat 0 "No onject" 1 "Object predicted" 2 "Object measured" 4 "Invalid" ;
VAL_ 864 RadarTar8_DynProp 0 "Unclassified" 1 "Stopped" 2 "Moving" 4 "Invalid" ;
VAL_ 864 RadarTar8_MgCnt_B 0 "counter0" 1 "counter1" 2 "counter2" 3 "counter3" ;
VAL_ 880 ME_TSR_HdMsgCnt 0 "counter0" 1 "counter1" 2 "counter2" 3 "counter3" ;
VAL_ 880 ME_TSR_HdMsg_V 0 "invalid" 1 "valid" ;
VAL_ 881 ME_TSR_MgCnt_1 0 "counter0" 1 "counter1" 2 "counter2" 3 "counter3" ;
VAL_ 881 ME_TSR_Mg_1_V 0 "invalid" 1 "valid" ;
VAL_ 882 ME_TSR_MgCnt_2 0 "counter0" 1 "counter1" 2 "counter2" 3 "counter3" ;
VAL_ 882 ME_TSR_Mg_2_V 0 "invalid" 1 "valid" ;
VAL_ 883 ME_TSR_MgCnt_3 0 "counter0" 1 "counter1" 2 "counter2" 3 "counter3" ;
VAL_ 883 ME_TSR_Mg_3_V 0 "invalid" 1 "valid" ;
VAL_ 884 ME_TSR_MgCnt_4 0 "counter0" 1 "counter1" 2 "counter2" 3 "counter3" ;
VAL_ 884 ME_TSR_Mg_4_V 0 "invalid" 1 "valid" ;
VAL_ 885 ME_TSR_MgCnt_5 0 "counter0" 1 "counter1" 2 "counter2" 3 "counter3" ;
VAL_ 885 ME_TSR_Mg_5_V 0 "invalid" 1 "valid" ;
VAL_ 886 ME_TSR_MgCnt_6 0 "counter0" 1 "counter1" 2 "counter2" 3 "counter3" ;
VAL_ 886 ME_TSR_Mg_6_V 0 "invalid" 1 "valid" ;
VAL_ 887 ME_AHLB_MgCnt 0 "counter0" 1 "counter1" 2 "counter2" 3 "counter3" ;
VAL_ 887 ME_AHLB_Mode 0 "invalid" 1 "HLB_Day" 2 "HLB_Inactive" 3 "HLB_Full" ;
VAL_ 887 ME_AHLB_decision 0 "HB Off" 1 "HB On" ;
VAL_ 887 ME_AHLB_RsPre 0 "Off" 1 "On" ;
VAL_ 887 ME_AHLB_RsPre_G 0 "Off" 1 "On" ;
VAL_ 887 ME_AHLB_RsOn 0 "Off" 1 "On" ;
VAL_ 887 ME_AHLB_RsOn_G 0 "Off" 1 "On" ;
VAL_ 887 ME_AHLB_RsStrLt 0 "Off" 1 "On" ;
VAL_ 887 ME_AHLB_RsStrLt_G 0 "Off" 1 "On" ;
VAL_ 887 ME_AHLB_RsLitNt 0 "Off" 1 "On" ;
VAL_ 887 ME_AHLB_RsLowSpd 0 "Off" 1 "On" ;
VAL_ 887 ME_AHLB_RsBrtSce 0 "Off" 1 "On" ;
VAL_ 887 ME_AHLB_RsShpCur 0 "Off" 1 "On" ;
VAL_ 887 ME_AHLB_Mg_V 0 "invalid" 1 "valid" ;
VAL_ 1199 MsgADAS10_State 0 "Normal" 1 "Timeout" ;
VAL_ 1199 MsgADAS11_State 0 "Normal" 1 "Timeout" ;
VAL_ 1199 MsgNMmM_State 0 "Normal" 1 "Timeout" ;
VAL_ 1199 EEPROM_State 0 "Normal" 1 "Failure" ;
VAL_ 1199 Flash_State 0 "Normal" 1 "Failure" ;
VAL_ 1199 EyeQ3_State 0 "Normal" 1 "Failure" ;
VAL_ 1199 Radar_State 0 "Normal" 1 "Failure" ;
VAL_ 1199 SPC_State 0 "Unavailable" 1 "Available" 2 "Running" ;
VAL_ 1552 Cm_Cali_Sta 0 "  Invalid" 1 "Calibration Succeeded" 2 "Calibration Failure" ;
VAL_ 1552 Radar_Cali_Sta 0 "No Error" 1 "Calibration Succeeded" 2 "Error1 (a lot of numbers of Targets)" 3 "Error2 (No Target)" 4 "Error3 (Abnormal Distance)" 5 "Error4 (Time Out)" 6 "Error5 (Abnormal Degree)" 7 "Error6 (Aiming Angle is already set)" 8 "Invalid" ;
VAL_ 1552 Radar_Cali_Ang 0 "Calibration Process is running" 1 "Calibration is not completed Calibration Angle is not set)" 2 "Invalid" ;
VAL_ 1552 Cm_Cali_SPTAC1_OK 0 "invalid" 1 "success" ;
VAL_ 1552 Cm_Cali_SPTAC2_OK 0 "invalid" 1 "success" ;
VAL_ 1552 Cm_Cali_TAC2_OK 0 "invalid" 1 "success" ;
VAL_ 1552 Cm_Cali_Failure 0 "invalid" 1 "failure" ;
VAL_ 1552 Cm_Cali_SPTAC_F_C 0 "NO_SPTAC_ERROR" 1 "UNKOWN_SPTAC_ERROR" 2 "SWITCH_CLOSE_FAR_SPTAC_ERROR" 3 "SAME_CLOSE_FAR_SPTAC_ERROR" 4 "LINE_MISMATCH_SPTAC_ERROR" 5 "FAR_CLOSE_ROLL_SPTAC_ERROR" 6 "LINE_NOT_FOUND_SPTAC_ERROR" 7 "BAD_IMAGE_SPTAC_ERROR" 8 "WRONG_STAGE_ERROR" 9 "ROLL_OUT_OF_RANGE" 10 "FOE_OUT_OF_RANGE" ;
VAL_ 1552 Cm_Cali_TAC2_F_C 0 "UNDEFINED" 1 "SUCCESS" 2 "TARGET_NOT_FOUND" 3 "ROLL_ANGLE_TOO_LARGE" 4 "FOE_OUT_OF_TOLERANCE" 5 "PARAMS_LOAD_FAILED" 6 "BAD_PARAMS_DISTANCE" 7 "BAD_PARAMS_SQUARE_SIDE_SIZE" 8 "BAD_PARAMS_TARGET_YAW" 9 "BAD_PARAMS_TARGET_HORIZON" 10 "TOO_MANY_TARGETS" 11 "RUN_ERROR" ;
VAL_ 1809 NM_SENP_D_ES 0 "Error Active State" 1 "Error Passive/Warning State" 2 "Bus Off State" 3 "Not used" ;
VAL_ 1809 NM_SENP_AR 0 "No Activation Request" 1 "Activation Request" ;
VAL_ 1809 NM_SENP_SC 0 "WU" 1 "Not Used" 2 "SA" 3 "Not Used" ;
VAL_ 1810 NM_ECU2_D_ES 0 "Error Active State" 1 "Error Passive/Warning State" 2 "Bus Off State" 3 "Not used" ;
VAL_ 1810 NM_ECU2_AR 0 "No Activation Request" 1 "Activation Request" ;
VAL_ 1810 NM_ECU2_SC 0 "WU" 1 "Not Used" 2 "SA" 3 "Not Used" ;
VAL_ 1811 NM_ECU3_D_ES 0 "Error Active State" 1 "Error Passive/Warning State" 2 "Bus Off State" 3 "Not used" ;
VAL_ 1811 NM_ECU3_AR 0 "No Activation Request" 1 "Activation Request" ;
VAL_ 1811 NM_ECU3_SC 0 "WU" 1 "Not Used" 2 "SA" 3 "Not Used" ;
VAL_ 1812 NM_ECU4_D_ES 0 "Error Active State" 1 "Error Passive/Warning State" 2 "Bus Off State" 3 "Not used" ;
VAL_ 1812 NM_ECU4_AR 0 "No Activation Request" 1 "Activation Request" ;
VAL_ 1812 NM_ECU4_SC 0 "WU" 1 "Not Used" 2 "SA" 3 "Not Used" ;
VAL_ 1813 NM_ECU5_D_ES 0 "Error Active State" 1 "Error Passive/Warning State" 2 "Bus Off State" 3 "Not used" ;
VAL_ 1813 NM_ECU5_AR 0 "No Activation Request" 1 "Activation Request" ;
VAL_ 1813 NM_ECU5_SC 0 "WU" 1 "Not Used" 2 "SA" 3 "Not Used" ;
VAL_ 1814 NM_ECU6_D_ES 0 "Error Active State" 1 "Error Passive/Warning State" 2 "Bus Off State" 3 "Not used" ;
VAL_ 1814 NM_ECU6_AR 0 "No Activation Request" 1 "Activation Request" ;
VAL_ 1814 NM_ECU6_SC 0 "WU" 1 "Not Used" 2 "SA" 3 "Not Used" ;
VAL_ 1815 NM_ECU7_D_ES 0 "Error Active State" 1 "Error Passive/Warning State" 2 "Bus Off State" 3 "Not used" ;
VAL_ 1815 NM_ECU7_AR 0 "No Activation Request" 1 "Activation Request" ;
VAL_ 1815 NM_ECU7_SC 0 "WU" 1 "Not Used" 2 "SA" 3 "Not Used" ;
VAL_ 1816 NM_ECU8_D_ES 0 "Error Active State" 1 "Error Passive/Warning State" 2 "Bus Off State" 3 "Not used" ;
VAL_ 1816 NM_ECU8_AR 0 "No Activation Request" 1 "Activation Request" ;
VAL_ 1816 NM_ECU8_SC 0 "WU" 1 "Not Used" 2 "SA" 3 "Not Used" ;
VAL_ 1817 NM_ECU9_D_ES 0 "Error Active State" 1 "Error Passive/Warning State" 2 "Bus Off State" 3 "Not used" ;
VAL_ 1817 NM_ECU9_AR 0 "No Activation Request" 1 "Activation Request" ;
VAL_ 1817 NM_ECU9_SC 0 "WU" 1 "Not Used" 2 "SA" 3 "Not Used" ;
VAL_ 1818 NM_ECU10_D_ES 0 "Error Active State" 1 "Error Passive/Warning State" 2 "Bus Off State" 3 "Not used" ;
VAL_ 1818 NM_ECU10_AR 0 "No Activation Request" 1 "Activation Request" ;
VAL_ 1818 NM_ECU10_SC 0 "WU" 1 "Not Used" 2 "SA" 3 "Not Used" ;
VAL_ 1819 NM_ECU11_D_ES 0 "Error Active State" 1 "Error Passive/Warning State" 2 "Bus Off State" 3 "Not used" ;
VAL_ 1819 NM_ECU11_AR 0 "No Activation Request" 1 "Activation Request" ;
VAL_ 1819 NM_ECU11_SC 0 "WU" 1 "Not Used" 2 "SA" 3 "Not Used" ;
VAL_ 1820 NM_ECU12_D_ES 0 "Error Active State" 1 "Error Passive/Warning State" 2 "Bus Off State" 3 "Not used" ;
VAL_ 1820 NM_ECU12_AR 0 "No Activation Request" 1 "Activation Request" ;
VAL_ 1820 NM_ECU12_SC 0 "WU" 1 "Not Used" 2 "SA" 3 "Not Used" ;
VAL_ 1821 NM_ECU13_D_ES 0 "Error Active State" 1 "Error Passive/Warning State" 2 "Bus Off State" 3 "Not used" ;
VAL_ 1821 NM_ECU13_AR 0 "No Activation Request" 1 "Activation Request" ;
VAL_ 1821 NM_ECU13_SC 0 "WU" 1 "Not Used" 2 "SA" 3 "Not Used" ;
VAL_ 1822 NM_ECU14_D_ES 0 "Error Active State" 1 "Error Passive/Warning State" 2 "Bus Off State" 3 "Not used" ;
VAL_ 1822 NM_ECU14_AR 0 "No Activation Request" 1 "Activation Request" ;
VAL_ 1822 NM_ECU14_SC 0 "WU" 1 "Not Used" 2 "SA" 3 "Not Used" ;
VAL_ 1823 NM_ECU15_D_ES 0 "Error Active State" 1 "Error Passive/Warning State" 2 "Bus Off State" 3 "Not used" ;
VAL_ 1823 NM_ECU15_AR 0 "No Activation Request" 1 "Activation Request" ;
VAL_ 1823 NM_ECU15_SC 0 "WU" 1 "Not Used" 2 "SA" 3 "Not Used" ;
